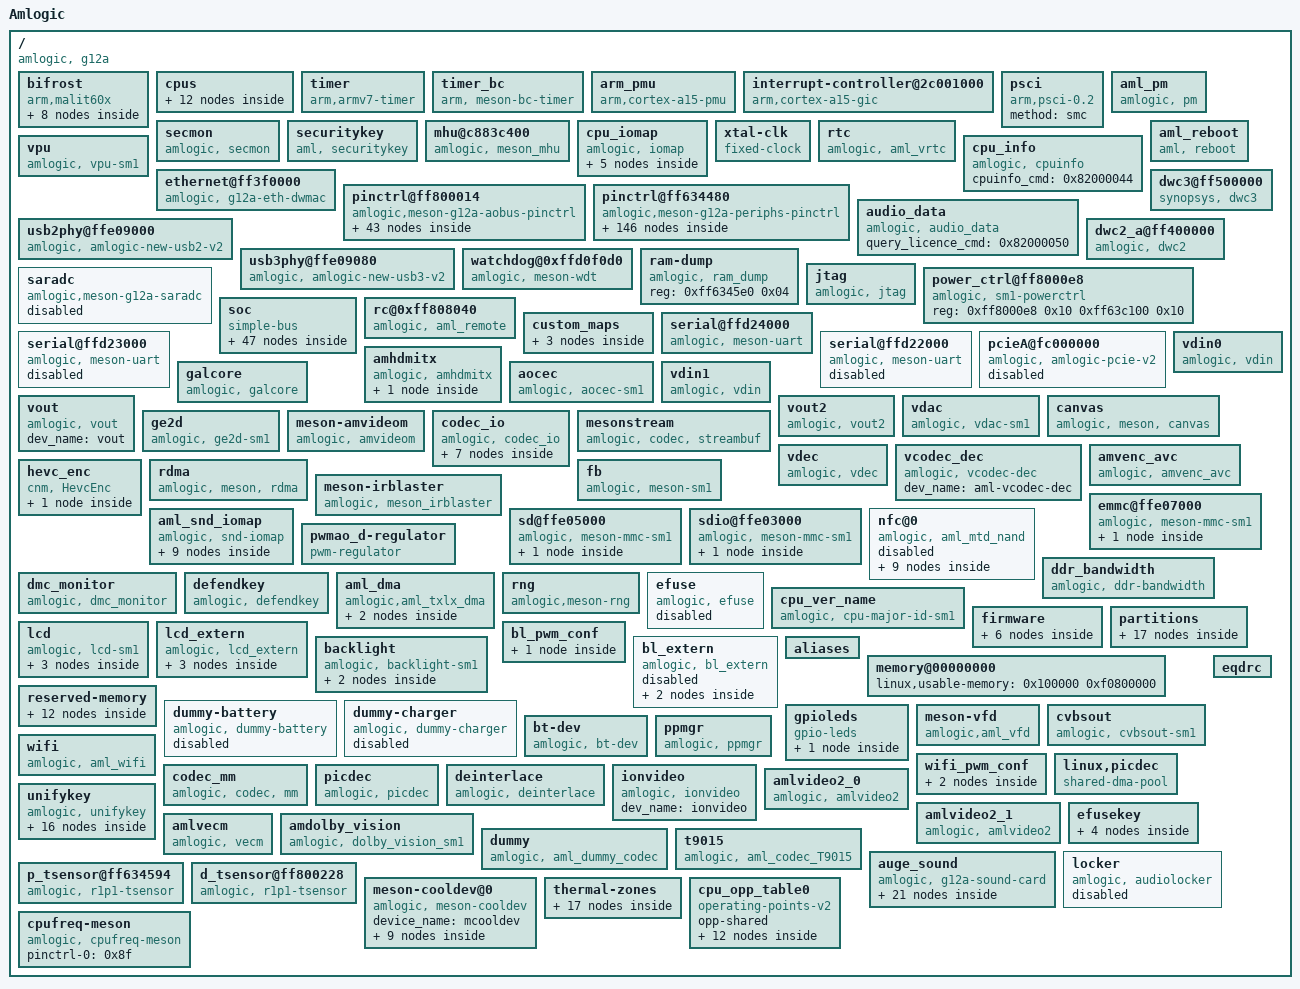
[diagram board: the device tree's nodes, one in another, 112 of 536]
/dts-v1/;

#include <dt-bindings/interrupt-controller/arm-gic.h>
#include <dt-bindings/clock/amlogic,g12a-clkc.h>
#include <dt-bindings/clock/amlogic,sm1-audio-clk.h>
#include <dt-bindings/iio/adc/amlogic-saradc.h>
#include <dt-bindings/gpio/meson-g12a-gpio.h>
#include <dt-bindings/pwm/pwm.h>
#include <dt-bindings/pwm/meson.h>
#include <dt-bindings/gpio/gpio.h>
#include <dt-bindings/input/input.h>
#include <dt-bindings/input/meson_rc.h>
#include <dt-bindings/phy/phy-amlogic-pcie.h>

/ {
	model = "Amlogic";
	amlogic-dt-id = "sm1_ac213_4g";
	compatible = "amlogic, g12a";
	interrupt-parent = <0x01>;
	#address-cells = <0x01>;
	#size-cells = <0x01>;

	bifrost {
		compatible = "arm,malit60x\0arm,malit6xx\0arm,mali-midgard";
		#cooling-cells = <0x02>;
		reg = <0xffe40000 0x4000 0xffd01000 0x1000 0xff800000 0x1000 0xff63c000 0x1000 0xffd01000 0x1000>;
		interrupt-parent = <0x01>;
		interrupts = <0x00 0xa0 0x04 0x00 0xa1 0x04 0x00 0xa2 0x04>;
		interrupt-names = "GPU\0MMU\0JOB";
		num_of_pp = <0x02>;
		sc_mpp = <0x01>;
		clocks = <0x02 0x83 0x02 0x07>;
		clock-names = "gpu_mux\0gp0_pll";
		tbl = <0x03 0x04 0x05 0x06 0x07 0x07>;
		phandle = <0x90>;

		clk125_cfg {
			clk_freq = <0x7735940>;
			clk_parent = "fclk_div4";
			clkp_freq = <0x1dcd6500>;
			clk_reg = <0xa03>;
			voltage = <0x47e>;
			keep_count = <0x05>;
			threshold = <0x1e 0x78>;
			phandle = <0x91>;
		};

		dvfs250_cfg {
			clk_freq = <0xee6b280>;
			clk_parent = "fclk_div4";
			clkp_freq = <0x1dcd6500>;
			clk_reg = <0xa01>;
			voltage = <0x47e>;
			keep_count = <0x05>;
			threshold = <0x50 0xaa>;
			phandle = <0x92>;
		};

		dvfs285_cfg {
			clk_freq = <0x1107a76d>;
			clk_parent = "fclk_div7";
			clkp_freq = <0x1107a76d>;
			clk_reg = <0xe00>;
			voltage = <0x47e>;
			keep_count = <0x05>;
			threshold = <0x64 0xbe>;
			phandle = <0x03>;
		};

		dvfs400_cfg {
			clk_freq = <0x17d78400>;
			clk_parent = "fclk_div5";
			clkp_freq = <0x17d78400>;
			clk_reg = <0xc00>;
			voltage = <0x47e>;
			keep_count = <0x05>;
			threshold = <0x98 0xcf>;
			phandle = <0x04>;
		};

		dvfs500_cfg {
			clk_freq = <0x1dcd6500>;
			clk_parent = "fclk_div4";
			clkp_freq = <0x1dcd6500>;
			clk_reg = <0xa00>;
			voltage = <0x47e>;
			keep_count = <0x05>;
			threshold = <0xb4 0xdc>;
			phandle = <0x05>;
		};

		dvfs666_cfg {
			clk_freq = <0x27bc86aa>;
			clk_parent = "fclk_div3";
			clkp_freq = <0x27bc86aa>;
			clk_reg = <0x800>;
			voltage = <0x47e>;
			keep_count = <0x05>;
			threshold = <0xd2 0xec>;
			phandle = <0x06>;
		};

		dvfs800_cfg {
			clk_freq = <0x2faf0800>;
			clk_parent = "fclk_div2p5";
			clkp_freq = <0x2faf0800>;
			clk_reg = <0x600>;
			voltage = <0x47e>;
			keep_count = <0x05>;
			threshold = <0xe6 0xff>;
			phandle = <0x93>;
		};

		dvfs850_cfg {
			clk_freq = <0x326cef80>;
			clk_parent = "gp0_pll";
			clkp_freq = <0x326cef80>;
			clk_reg = <0x200>;
			voltage = <0x47e>;
			keep_count = <0x05>;
			threshold = <0xe6 0xff>;
			phandle = <0x07>;
		};
	};

	cpus {
		#address-cells = <0x01>;
		#size-cells = <0x00>;
		phandle = <0x94>;

		cpu-map {

			cluster0 {
				phandle = <0x95>;

				core0 {
					cpu = <0x08>;
				};

				core1 {
					cpu = <0x09>;
				};

				core2 {
					cpu = <0x0a>;
				};

				core3 {
					cpu = <0x0b>;
				};
			};
		};

		cpu@0 {
			device_type = "cpu";
			compatible = "arm,cortex-a53\0arm,armv8";
			reg = <0x00>;
			enable-method = "psci";
			cpu-idle-states = <0x0c>;
			clocks = <0x02 0x17 0x02 0x16 0x02 0x00 0x02 0xf8 0x02 0xf7>;
			clock-names = "core_clk\0low_freq_clk_parent\0high_freq_clk_parent\0dsu_clk\0dsu_pre_parent";
			operating-points-v2 = <0x0d>;
			cpu-supply = <0x0e>;
			voltage-tolerance = <0x00>;
			clock-latency = <0xc350>;
			phandle = <0x08>;
		};

		cpu@1 {
			device_type = "cpu";
			compatible = "arm,cortex-a53\0arm,armv8";
			reg = <0x01>;
			enable-method = "psci";
			cpu-idle-states = <0x0c>;
			clocks = <0x02 0x17 0x02 0x16 0x02 0x00 0x02 0xf8 0x02 0xf7>;
			clock-names = "core_clk\0low_freq_clk_parent\0high_freq_clk_parent\0dsu_clk\0dsu_pre_parent";
			operating-points-v2 = <0x0d>;
			cpu-supply = <0x0e>;
			voltage-tolerance = <0x00>;
			clock-latency = <0xc350>;
			phandle = <0x09>;
		};

		cpu@2 {
			device_type = "cpu";
			compatible = "arm,cortex-a53\0arm,armv8";
			reg = <0x02>;
			enable-method = "psci";
			cpu-idle-states = <0x0c>;
			clocks = <0x02 0x17 0x02 0x16 0x02 0x00 0x02 0xf8 0x02 0xf7>;
			clock-names = "core_clk\0low_freq_clk_parent\0high_freq_clk_parent\0dsu_clk\0dsu_pre_parent";
			operating-points-v2 = <0x0d>;
			cpu-supply = <0x0e>;
			voltage-tolerance = <0x00>;
			clock-latency = <0xc350>;
			phandle = <0x0a>;
		};

		cpu@3 {
			device_type = "cpu";
			compatible = "arm,cortex-a53\0arm,armv8";
			reg = <0x03>;
			enable-method = "psci";
			cpu-idle-states = <0x0c>;
			clocks = <0x02 0x17 0x02 0x16 0x02 0x00 0x02 0xf8 0x02 0xf7>;
			clock-names = "core_clk\0low_freq_clk_parent\0high_freq_clk_parent\0dsu_clk\0dsu_pre_parent";
			operating-points-v2 = <0x0d>;
			cpu-supply = <0x0e>;
			voltage-tolerance = <0x00>;
			clock-latency = <0xc350>;
			phandle = <0x0b>;
		};

		idle-states {
			entry-method = "arm,psci-0.2";

			cpu-sleep-0 {
				compatible = "arm,idle-state";
				arm,psci-suspend-param = <0x10000>;
				local-timer-stop;
				entry-latency-us = <0xfa0>;
				exit-latency-us = <0x1388>;
				min-residency-us = <0x2710>;
				phandle = <0x0c>;
			};
		};
	};

	timer {
		compatible = "arm,armv7-timer";
		interrupts = <0x01 0x0d 0xff08 0x01 0x0e 0xff08 0x01 0x0b 0xff08 0x01 0x0a 0xff08>;
	};

	timer_bc {
		compatible = "arm, meson-bc-timer";
		reg = <0xffd0f190 0x04 0xffd0f194 0x04>;
		timer_name = "Meson TimerF";
		clockevent-rating = <0x12c>;
		clockevent-shift = <0x14>;
		clockevent-features = <0x23>;
		interrupts = <0x00 0x3c 0x01>;
		bit_enable = <0x10>;
		bit_mode = <0x0c>;
		bit_resolution = <0x00>;
	};

	arm_pmu {
		compatible = "arm,cortex-a15-pmu";
		interrupts = <0x00 0x89 0x04>;
		reg = <0xff634680 0x04>;
		cpumasks = <0x0f>;
		relax-timer-ns = <0x989680>;
		max-wait-cnt = <0x2710>;
	};

	interrupt-controller@2c001000 {
		compatible = "arm,cortex-a15-gic\0arm,cortex-a9-gic";
		#interrupt-cells = <0x03>;
		#address-cells = <0x00>;
		interrupt-controller;
		reg = <0xffc01000 0x1000 0xffc02000 0x100>;
		interrupts = <0x01 0x09 0xf04>;
		phandle = <0x01>;
	};

	psci {
		compatible = "arm,psci-0.2";
		method = "smc";
	};

	aml_pm {
		compatible = "amlogic, pm";
		status = "okay";
		device_name = "aml_pm";
		debug_reg = <0xff8000a8>;
		exit_reg = <0xff80023c>;
	};

	secmon {
		compatible = "amlogic, secmon";
		memory-region = <0x0f>;
		in_base_func = <0x82000020>;
		out_base_func = <0x82000021>;
		reserve_mem_size = <0x300000>;
	};

	securitykey {
		compatible = "aml, securitykey";
		storage_query = <0x82000060>;
		storage_read = <0x82000061>;
		storage_write = <0x82000062>;
		storage_tell = <0x82000063>;
		storage_verify = <0x82000064>;
		storage_status = <0x82000065>;
		storage_list = <0x82000067>;
		storage_remove = <0x82000068>;
		storage_in_func = <0x82000023>;
		storage_out_func = <0x82000024>;
		storage_block_func = <0x82000025>;
		storage_size_func = <0x82000027>;
		storage_set_enctype = <0x8200006a>;
		storage_get_enctype = <0x8200006b>;
		storage_version = <0x8200006c>;
	};

	mhu@c883c400 {
		compatible = "amlogic, meson_mhu";
		reg = <0xff63c400 0x4c 0xfffe7000 0x800>;
		interrupts = <0x00 0xd1 0x01 0x00 0xd2 0x01>;
		#mbox-cells = <0x01>;
		mbox-names = "cpu_to_scp_low\0cpu_to_scp_high";
		mboxes = <0x10 0x00 0x10 0x01>;
		phandle = <0x10>;
	};

	cpu_iomap {
		compatible = "amlogic, iomap";
		#address-cells = <0x01>;
		#size-cells = <0x01>;
		ranges;

		io_cbus_base {
			reg = <0xffd00000 0x26fff>;
		};

		io_apb_base {
			reg = <0xffe01000 0x7f000>;
		};

		io_aobus_base {
			reg = <0xff800000 0xb000>;
		};

		io_vapb_base {
			reg = <0xff900000 0x50000>;
		};

		io_hiu_base {
			reg = <0xff63c000 0x2000>;
		};
	};

	xtal-clk {
		compatible = "fixed-clock";
		clock-frequency = <0x16e3600>;
		clock-output-names = "xtal";
		#clock-cells = <0x00>;
		phandle = <0x14>;
	};

	rtc {
		compatible = "amlogic, aml_vrtc";
		alarm_reg_addr = <0xff8000a8>;
		timer_e_addr = <0xffd0f188>;
		init_date = "2015/01/01";
		status = "okay";
	};

	cpu_info {
		compatible = "amlogic, cpuinfo";
		status = "okay";
		cpuinfo_cmd = <0x82000044>;
	};

	aml_reboot {
		compatible = "aml, reboot";
		sys_reset = <0x84000009>;
		sys_poweroff = <0x84000008>;
	};

	vpu {
		compatible = "amlogic, vpu-sm1";
		dev_name = "vpu";
		status = "okay";
		clocks = <0x02 0x95 0x02 0x4c 0x02 0x87 0x02 0x8b 0x02 0x8c>;
		clock-names = "vapb_clk\0vpu_intr_gate\0vpu_clk0\0vpu_clk1\0vpu_clk";
		clk_level = <0x07>;
		phandle = <0x96>;
	};

	ethernet@ff3f0000 {
		compatible = "amlogic, g12a-eth-dwmac\0snps,dwmac";
		reg = <0xff3f0000 0x10000 0xff634540 0x08 0xff64c000 0xa0 0xffd01008 0x04>;
		reg-names = "eth_base\0eth_cfg\0eth_pll\0eth_reset";
		interrupts = <0x00 0x08 0x01>;
		interrupt-names = "macirq";
		status = "okay";
		clocks = <0x02 0x38>;
		clock-names = "ethclk81";
		pll_val = <0x9c0040a 0x927e0000 0xac5f49e5>;
		analog_val = <0x20200000 0xc000 0x23>;
		pinctrl-names = "external_eth_pins";
		pinctrl-0 = <0x11>;
		mc_val = <0x1621>;
		cali_val = <0x30000>;
		internal_phy = <0x00>;
		phandle = <0x97>;
	};

	pinctrl@ff800014 {
		compatible = "amlogic,meson-g12a-aobus-pinctrl";
		#address-cells = <0x01>;
		#size-cells = <0x01>;
		ranges;
		phandle = <0x98>;

		ao-bank@ff800014 {
			reg = <0xff800014 0x08 0xff800024 0x14 0xff80001c 0x08>;
			reg-names = "mux\0gpio\0drive-strength";
			gpio-controller;
			#gpio-cells = <0x02>;
			phandle = <0x63>;
		};

		sd_to_ao_uart_clr_pins {
			phandle = <0x43>;

			mux {
				groups = "GPIOAO_0\0GPIOAO_1";
				function = "gpio_aobus";
			};
		};

		sd_to_ao_uart_pins {
			phandle = <0x45>;

			mux {
				groups = "uart_ao_tx_a\0uart_ao_rx_a";
				function = "uart_ao_a";
				bias-pull-up;
				input-enable;
			};
		};

		ao_uart {
			phandle = <0x99>;

			mux {
				groups = "uart_ao_tx_a\0uart_ao_rx_a";
				function = "uart_ao_a";
			};
		};

		ao_b_uart {
			phandle = <0x1c>;

			mux {
				groups = "uart_ao_tx_b_2\0uart_ao_rx_b_3";
				function = "uart_ao_b";
			};
		};

		ao_i2c_pins1 {
			phandle = <0x9a>;

			mux {
				groups = "i2c_ao_sck\0i2c_ao_sda";
				function = "i2c_ao";
				drive-strength = <0x02>;
			};
		};

		ao_i2c_pins2 {
			phandle = <0x9b>;

			mux {
				groups = "i2c_ao_sck_e\0i2c_ao_sda_e";
				function = "i2c_ao";
				drive-strength = <0x02>;
			};
		};

		ao_i2c_slave_pins {
			phandle = <0x1b>;

			mux {
				groups = "i2c_ao_slave_sck\0i2c_ao_slave_sda";
				function = "i2c_ao_slave";
			};
		};

		pwm_ao_a {
			phandle = <0x9c>;

			mux {
				groups = "pwm_ao_a";
				function = "pwm_ao_a";
			};
		};

		pwm_ao_a_hiz {
			phandle = <0x9d>;

			mux {
				groups = "pwm_ao_a_hiz";
				function = "pwm_ao_a";
			};
		};

		pwm_ao_b {
			phandle = <0x9e>;

			mux {
				groups = "pwm_ao_b";
				function = "pwm_ao_b";
			};
		};

		pwm_ao_c_pins1 {
			phandle = <0x9f>;

			mux {
				groups = "pwm_ao_c_4";
				function = "pwm_ao_c";
			};
		};

		pwm_ao_c_pins2 {
			phandle = <0xa0>;

			mux {
				groups = "pwm_ao_c_6";
				function = "pwm_ao_c";
			};
		};

		pwm_ao_c_hiz {
			phandle = <0xa1>;

			mux {
				groups = "pwm_ao_c_hiz_4";
				function = "pwm_ao_c";
			};
		};

		pwm_ao_d_pins1 {
			phandle = <0xa2>;

			mux {
				groups = "pwm_ao_d_5";
				function = "pwm_ao_d";
			};
		};

		pwm_ao_d_pins2 {
			phandle = <0xa3>;

			mux {
				groups = "pwm_ao_d_10";
				function = "pwm_ao_d";
			};
		};

		pwm_ao_d_pins3 {
			phandle = <0x8f>;

			mux {
				groups = "pwm_ao_d_e";
				function = "pwm_ao_d";
			};
		};

		ao_ceca {
			phandle = <0xa4>;

			mux {
				groups = "cec_ao_a";
				function = "cec_ao";
			};
		};

		ao_cecb {
			phandle = <0xa5>;

			mux {
				groups = "cec_ao_b";
				function = "cec_ao";
			};
		};

		jtag_apao_pin {
			phandle = <0x15>;

			mux {
				groups = "jtag_a_tdi\0jtag_a_tdo\0jtag_a_clk\0jtag_a_tms";
				function = "jtag_a";
			};
		};

		remote_pin {
			phandle = <0x2a>;

			mux {
				groups = "remote_input_ao";
				function = "remote_input_ao";
			};
		};

		irblaster_pin {
			phandle = <0x3c>;

			mux {
				groups = "remote_out_ao";
				function = "remote_out_ao";
			};
		};
	};

	pinctrl@ff634480 {
		compatible = "amlogic,meson-g12a-periphs-pinctrl";
		#address-cells = <0x01>;
		#size-cells = <0x01>;
		ranges;
		phandle = <0xa6>;

		banks@ff6346c0 {
			reg = <0xff6346c0 0x40 0xff6344e8 0x18 0xff634520 0x18 0xff634440 0x4c 0xff634740 0x1c>;
			reg-names = "mux\0pull\0pull-enable\0gpio\0drive-strength";
			gpio-controller;
			#gpio-cells = <0x02>;
			phandle = <0x18>;
		};

		emmc_clk_cmd_pins {
			phandle = <0x3d>;

			mux {
				groups = "emmc_clk\0emmc_cmd";
				function = "emmc";
				input-enable;
				bias-pull-up;
				drive-strength = <0x03>;
			};
		};

		emmc_conf_pull_up {
			phandle = <0x3e>;

			mux {
				groups = "emmc_nand_d7\0emmc_nand_d6\0emmc_nand_d5\0emmc_nand_d4\0emmc_nand_d3\0emmc_nand_d2\0emmc_nand_d1\0emmc_nand_d0\0emmc_clk\0emmc_cmd";
				function = "emmc";
				input-enable;
				bias-pull-up;
				drive-strength = <0x03>;
			};
		};

		emmc_conf_pull_done {
			phandle = <0x3f>;

			mux {
				groups = "emmc_nand_ds";
				function = "emmc";
				input-enable;
				bias-pull-down;
				drive-strength = <0x03>;
			};
		};

		sd_clk_cmd_pins {
			phandle = <0x41>;

			mux {
				groups = "sdcard_cmd_c";
				function = "sdcard";
				input-enable;
				bias-pull-up;
				drive-strength = <0x03>;
			};

			mux1 {
				groups = "sdcard_clk_c";
				function = "sdcard";
				bias-pull-up;
				output-high;
				drive-strength = <0x03>;
			};
		};

		sd_all_pins {
			phandle = <0x40>;

			mux {
				groups = "sdcard_d0_c\0sdcard_d1_c\0sdcard_d2_c\0sdcard_d3_c\0sdcard_cmd_c";
				function = "sdcard";
				input-enable;
				bias-pull-up;
				drive-strength = <0x03>;
			};

			mux1 {
				groups = "sdcard_clk_c";
				function = "sdcard";
				bias-pull-up;
				output-high;
				drive-strength = <0x03>;
			};
		};

		sd_1bit_pins {
			phandle = <0x42>;

			mux {
				groups = "sdcard_d0_c\0sdcard_cmd_c";
				function = "sdcard";
				input-enable;
				bias-pull-up;
				drive-strength = <0x03>;
			};

			mux1 {
				groups = "sdcard_clk_c";
				function = "sdcard";
				bias-pull-up;
				output-high;
				drive-strength = <0x03>;
			};
		};

		sd_clr_all_pins {
			phandle = <0xa7>;

			mux {
				groups = "GPIOC_0\0GPIOC_1\0GPIOC_2\0GPIOC_3\0GPIOC_5";
				function = "gpio_periphs";
				output-high;
			};

			mux1 {
				groups = "GPIOC_4";
				function = "gpio_periphs";
				output-low;
			};
		};

		sd_clr_noall_pins {
			phandle = <0xa8>;

			mux {
				groups = "GPIOC_0\0GPIOC_1\0GPIOC_4\0GPIOC_5";
				function = "gpio_periphs";
				output-high;
			};
		};

		ao_to_sd_uart_pins {
			phandle = <0x44>;

			mux {
				groups = "uart_ao_tx_a_c3\0uart_ao_rx_a_c2";
				function = "uart_ao_a_ee";
				bias-pull-up;
				input-enable;
			};
		};

		sdio_clk_cmd_pins {
			phandle = <0x47>;

			mux {
				groups = "sdio_clk\0sdio_cmd";
				function = "sdio";
				input-enable;
				bias-pull-up;
				drive-strength = <0x03>;
			};
		};

		sdio_all_pins {
			phandle = <0x46>;

			mux {
				groups = "sdio_d0\0sdio_d1\0sdio_d2\0sdio_d3\0sdio_clk\0sdio_cmd";
				function = "sdio";
				input-enable;
				bias-pull-up;
				drive-strength = <0x03>;
			};
		};

		sdio_x_clk_cmd_pins {
			phandle = <0xa9>;

			mux {
				groups = "GPIOX_5";
				function = "gpio_periphs";
				input-enable;
				bias-pull-up;
				drive-strength = <0x03>;
			};

			mux1 {
				groups = "GPIOX_4";
				function = "gpio_periphs";
				bias-pull-up;
				output-high;
				drive-strength = <0x03>;
			};
		};

		sdio_x_all_pins {
			phandle = <0xaa>;

			mux {
				groups = "GPIOX_0\0GPIOX_1\0GPIOX_2\0GPIOX_3\0GPIOX_5";
				function = "gpio_periphs";
				input-enable;
				bias-pull-up;
				drive-strength = <0x03>;
			};

			mux1 {
				groups = "GPIOX_4";
				function = "gpio_periphs";
				bias-pull-up;
				output-high;
				drive-strength = <0x03>;
			};
		};

		sdio_x_en_pins {
			phandle = <0xab>;

			mux {
				groups = "sdio_dummy";
				function = "sdio";
				bias-pull-up;
				output-high;
			};
		};

		sdio_x_clr_pins {
			phandle = <0xac>;

			mux {
				groups = "GPIOV_0";
				function = "gpio_periphs";
				bias-pull-up;
				output-low;
			};

			mux1 {
				groups = "GPIOX_4";
				function = "gpio_periphs";
				output-low;
			};
		};

		all_nand_pins {
			phandle = <0x48>;

			mux {
				groups = "emmc_nand_d0\0emmc_nand_d1\0emmc_nand_d2\0emmc_nand_d3\0emmc_nand_d4\0emmc_nand_d5\0emmc_nand_d6\0emmc_nand_d7\0nand_ce0\0nand_ale\0nand_cle\0nand_wen_clk\0nand_ren_wr\0nand_rb0";
				function = "nand";
				input-enable;
			};
		};

		nand_cs {
			phandle = <0x49>;

			mux {
				groups = "nand_ce0";
				function = "nand";
			};
		};

		i2c0_pins1 {
			phandle = <0xad>;

			mux {
				groups = "i2c0_sda_c\0i2c0_sck_c";
				function = "i2c0";
				drive-strength = <0x02>;
			};
		};

		i2c0_pins2 {
			phandle = <0x17>;

			mux {
				groups = "i2c0_sda_z0\0i2c0_sck_z1";
				function = "i2c0";
				drive-strength = <0x02>;
			};
		};

		i2c0_pins3 {
			phandle = <0xae>;

			mux {
				groups = "i2c0_sda_z7\0i2c0_sck_z8";
				function = "i2c0";
				drive-strength = <0x02>;
			};
		};

		i2c1_pins1 {
			phandle = <0xaf>;

			mux {
				groups = "i2c1_sda_x\0i2c1_sck_x";
				function = "i2c1";
				drive-strength = <0x02>;
			};
		};

		i2c1_pins2 {
			phandle = <0xb0>;

			mux {
				groups = "i2c1_sda_h2\0i2c1_sck_h3";
				function = "i2c1";
				drive-strength = <0x02>;
			};
		};

		i2c1_pins3 {
			phandle = <0x19>;

			mux {
				groups = "i2c1_sda_h6\0i2c1_sck_h7";
				function = "i2c1";
				drive-strength = <0x02>;
			};
		};

		i2c2_pins1 {
			phandle = <0xb1>;

			mux {
				groups = "i2c2_sda_x\0i2c2_sck_x";
				function = "i2c2";
				drive-strength = <0x02>;
			};
		};

		i2c2_pins2 {
			phandle = <0xb2>;

			mux {
				groups = "i2c2_sda_z\0i2c2_sck_z";
				function = "i2c2";
				drive-strength = <0x02>;
			};
		};

		i2c2_pins3 {
			phandle = <0xb3>;

			mux {
				groups = "i2c2_sda_z10\0i2c2_sck_z11";
				function = "i2c2";
				drive-strength = <0x02>;
			};
		};

		i2c3_pins1 {
			phandle = <0x36>;

			mux {
				groups = "i2c3_sda_h\0i2c3_sck_h";
				function = "i2c3";
				drive-strength = <0x02>;
			};
		};

		i2c3_pins2 {
			phandle = <0x1a>;

			mux {
				function = "i2c3";
				drive-strength = <0x02>;
			};
		};

		pwm_a {
			phandle = <0xb4>;

			mux {
				groups = "pwm_a";
				function = "pwm_a";
			};
		};

		pwm_b_pins1 {
			phandle = <0xb5>;

			mux {
				groups = "pwm_b_x7";
				function = "pwm_b";
			};
		};

		pwm_b_pins2 {
			phandle = <0xb6>;

			mux {
				groups = "pwm_b_x19";
				function = "pwm_b";
			};
		};

		pwm_c_pins1 {
			phandle = <0xb7>;

			mux {
				groups = "pwm_c_c4";
				function = "pwm_c";
			};
		};

		pwm_c_pins2 {
			phandle = <0xb8>;

			mux {
				groups = "pwm_c_x5";
				function = "pwm_c";
			};
		};

		pwm_c_pins3 {
			phandle = <0xb9>;

			mux {
				groups = "pwm_c_x8";
				function = "pwm_c";
			};
		};

		pwm_d_pins1 {
			phandle = <0xba>;

			mux {
				groups = "pwm_d_x3";
				function = "pwm_d";
			};
		};

		pwm_d_pins2 {
			phandle = <0xbb>;

			mux {
				groups = "pwm_d_x6";
				function = "pwm_d";
			};
		};

		pwm_e {
			phandle = <0x64>;

			mux {
				groups = "pwm_e";
				function = "pwm_e";
			};
		};

		pwm_f_pins1 {
			phandle = <0xbc>;

			mux {
				groups = "pwm_f_x";
				function = "pwm_f";
			};
		};

		pwm_f_pins2 {
			phandle = <0x60>;

			mux {
				groups = "pwm_f_h";
				function = "pwm_f";
			};
		};

		spicc0_pins_x {
			phandle = <0xbd>;

			mux {
				groups = "spi0_mosi_x\0spi0_miso_x\0spi0_clk_x";
				function = "spi0";
				drive-strength = <0x01>;
			};
		};

		spicc0_pins_c {
			phandle = <0xbe>;

			mux {
				groups = "spi0_mosi_c\0spi0_miso_c\0spi0_ss0_c\0spi0_clk_c";
				function = "spi0";
				drive-strength = <0x01>;
			};
		};

		spicc1_pins {
			phandle = <0xbf>;

			mux {
				groups = "spi1_mosi\0spi1_miso\0spi1_clk";
				function = "spi1";
				drive-strength = <0x01>;
			};
		};

		a_uart {
			phandle = <0x2f>;

			mux {
				groups = "uart_tx_a\0uart_rx_a\0uart_cts_a\0uart_rts_a";
				function = "uart_a";
			};
		};

		b_uart {
			phandle = <0x30>;

			mux {
				groups = "uart_tx_b\0uart_rx_b";
				function = "uart_b";
			};
		};

		c_uart {
			phandle = <0x31>;

			mux {
				groups = "uart_tx_c\0uart_rx_c";
				function = "uart_c";
			};
		};

		hdmitx_hpd {
			phandle = <0x33>;

			mux {
				groups = "hdmitx_hpd_in";
				function = "hdmitx";
				bias-disable;
			};
		};

		hdmitx_hpd_gpio {
			phandle = <0x35>;

			mux {
				groups = "GPIOH_1";
				function = "gpio_periphs";
				bias-disable;
			};
		};

		hdmitx_ddc {
			phandle = <0x34>;

			mux {
				groups = "hdmitx_sda\0hdmitx_sck";
				function = "hdmitx";
				bias-disable;
				drive-strength = <0x03>;
			};
		};

		ee_ceca {
			phandle = <0x37>;

			mux {
				groups = "cec_ao_a_ee";
				function = "cec_ao_ee";
			};
		};

		ee_cecb {
			phandle = <0x38>;

			mux {
				groups = "cec_ao_b_ee";
				function = "cec_ao_ee";
			};
		};

		internal_eth_pins {
			phandle = <0xc0>;

			mux {
				function = "eth";
			};
		};

		internal_gpio_pins {
			phandle = <0xc1>;

			mux {
				function = "gpio_periphs";
				bias-disable;
				input-enable;
			};
		};

		external_eth_pins {
			phandle = <0x11>;

			mux {
				groups = "eth_mdio\0eth_mdc\0eth_rgmii_rx_clk\0eth_rx_dv\0eth_rxd0\0eth_rxd1\0eth_rxd2_rgmii\0eth_rxd3_rgmii\0eth_rgmii_tx_clk\0eth_txen\0eth_txd0\0eth_txd1\0eth_txd2_rgmii\0eth_txd3_rgmii";
				function = "eth";
				drive-strength = <0x03>;
			};
		};

		jtag_apee_pin {
			phandle = <0x16>;

			mux {
				groups = "jtag_b_tdi\0jtag_b_tdo\0jtag_b_clk\0jtag_b_tms";
				function = "jtag_b";
			};
		};

		tdmout_a {
			phandle = <0x1f>;

			mux {
				groups = "tdma_sclk\0tdma_fs\0tdma_dout0";
				function = "tdma_out";
			};
		};

		tdmin_a {
			phandle = <0x20>;

			mux {
				groups = "tdma_din1";
				function = "tdma_in";
			};
		};

		tdmb_mclk {
			phandle = <0x21>;

			mux {
				groups = "mclk0_a";
				function = "mclk0";
				drive-strength = <0x02>;
			};
		};

		tdmout_b {
			phandle = <0x22>;

			mux {
				groups = "tdmb_sclk\0tdmb_fs\0tdmb_dout0";
				function = "tdmb_out";
				drive-strength = <0x02>;
			};
		};

		tdmin_b {
			phandle = <0x23>;

			mux {
				groups = "tdmb_din1";
				function = "tdmb_in";
				drive-strength = <0x02>;
			};
		};

		tdmc_mclk {
			phandle = <0x24>;

			mux {
				groups = "mclk1_a";
				function = "mclk1";
			};
		};

		tdmout_c {
			phandle = <0x25>;

			mux {
				groups = "tdmc_sclk_a\0tdmc_fs_a\0tdmc_dout0_a";
				function = "tdmc_out";
			};
		};

		tdmin_c {
			phandle = <0x26>;

			mux {
				groups = "tdmc_din0_a";
				function = "tdmc_in";
			};
		};

		spdifin {
			phandle = <0x28>;

			mux {
				groups = "spdif_in_h";
				function = "spdif_in";
			};
		};

		pdmin {
			phandle = <0x29>;

			mux {
				groups = "pdm_din0_a\0pdm_din2_a\0pdm_dclk_a";
				function = "pdm";
			};
		};

		bl_pwm_off_pin {
			phandle = <0xc2>;

			mux {
				pins = "GPIOH_5";
				function = "gpio_periphs";
				output-high;
			};
		};

		clk12_24_z_pins {
			phandle = <0xc3>;

			mux {
				groups = "clk12_24_z";
				function = "clk12_24_ee";
				drive-strength = <0x03>;
			};
		};

		gen_clk_ee_z {
			phandle = <0xc4>;

			mux {
				groups = "gen_clk_ee_z";
				function = "gen_clk_ee";
				drive-strength = <0x03>;
			};
		};

		cam_dvp_pins {
			phandle = <0xc5>;

			mux {
				groups = "bt656_a_vs\0bt656_a_hs\0bt656_a_clk\0bt656_a_din0\0bt656_a_din1\0bt656_a_din2\0bt656_a_din3\0bt656_a_din4\0bt656_a_din5\0bt656_a_din6\0bt656_a_din7";
				function = "bt656";
			};
		};

		spdifout {
			phandle = <0x27>;

			mux {
				groups = "spdif_out_h";
				function = "spdif_out";
			};
		};
	};

	audio_data {
		compatible = "amlogic, audio_data";
		query_licence_cmd = <0x82000050>;
		status = "okay";
		phandle = <0xc6>;
	};

	dwc3@ff500000 {
		compatible = "synopsys, dwc3";
		status = "okay";
		reg = <0xff500000 0x100000>;
		interrupts = <0x00 0x1e 0x04>;
		usb-phy = <0x12 0x13>;
		cpu-type = "gxl";
		clock-src = "usb3.0";
		clocks = <0x02 0x41>;
		clock-names = "dwc_general";
		phandle = <0xc7>;
	};

	usb2phy@ffe09000 {
		compatible = "amlogic, amlogic-new-usb2-v2";
		status = "okay";
		reg = <0xffe09000 0x80 0xffd01008 0x100 0xff636000 0x2000 0xff63a000 0x2000>;
		pll-setting-1 = <0x9400414>;
		pll-setting-2 = <0x927e0000>;
		pll-setting-3 = <0xac5f69e5>;
		pll-setting-4 = <0xfe18>;
		pll-setting-5 = <0x8000fff>;
		pll-setting-6 = <0x78000>;
		pll-setting-7 = <0xe0004>;
		pll-setting-8 = <0xe000c>;
		version = <0x02>;
		pwr-ctl = <0x01>;
		u2-ctrl-sleep-shift = <0x11>;
		u2-hhi-mem-pd-shift = <0x1e>;
		u2-hhi-mem-pd-mask = <0x03>;
		u2-ctrl-iso-shift = <0x11>;
		portnum = <0x02>;
		phandle = <0x12>;
	};

	usb3phy@ffe09080 {
		compatible = "amlogic, amlogic-new-usb3-v2";
		status = "okay";
		reg = <0xffe09080 0x20 0xffd01008 0x100>;
		phy-reg = <0xff646000>;
		phy-reg-size = <0x2000>;
		usb2-phy-reg = <0xffe09000>;
		usb2-phy-reg-size = <0x80>;
		interrupts = <0x00 0x10 0x04>;
		clocks = <0x02 0x18>;
		clock-names = "pcie_refpll";
		pwr-ctl = <0x01>;
		u3-ctrl-sleep-shift = <0x12>;
		u3-hhi-mem-pd-shift = <0x1a>;
		u3-hhi-mem-pd-mask = <0x0f>;
		u3-ctrl-iso-shift = <0x12>;
		portnum = <0x01>;
		otg = <0x00>;
		phandle = <0x13>;
	};

	dwc2_a@ff400000 {
		compatible = "amlogic, dwc2";
		status = "okay";
		device_name = "dwc2_a";
		reg = <0xff400000 0x40000>;
		interrupts = <0x00 0x1f 0x04>;
		pl-periph-id = <0x00>;
		clock-src = "usb0";
		port-id = <0x00>;
		port-type = <0x02>;
		port-speed = <0x00>;
		port-config = <0x00>;
		port-dma = <0x00>;
		port-id-mode = <0x00>;
		usb-fifo = <0x2d8>;
		cpu-type = "v2";
		phy-reg = <0xffe09000>;
		phy-reg-size = <0xa0>;
		phy-interface = <0x02>;
		clocks = <0x02 0x41 0x02 0x49>;
		clock-names = "usb_general\0usb1";
		controller-type = <0x01>;
		phandle = <0xc8>;
	};

	watchdog@0xffd0f0d0 {
		compatible = "amlogic, meson-wdt";
		status = "okay";
		default_timeout = <0x0a>;
		reset_watchdog_method = <0x01>;
		reset_watchdog_time = <0x02>;
		shutdown_timeout = <0x0a>;
		firmware_timeout = <0x06>;
		suspend_timeout = <0x06>;
		reg = <0xffd0f0d0 0x10>;
		clock-names = "xtal";
		clocks = <0x14>;
		phandle = <0xc9>;
	};

	ram-dump {
		compatible = "amlogic, ram_dump";
		status = "okay";
		reg = <0xff6345e0 0x04>;
		reg-names = "PREG_STICKY_REG8";
	};

	jtag {
		compatible = "amlogic, jtag";
		status = "okay";
		select = "disable";
		pinctrl-names = "jtag_apao_pins\0jtag_apee_pins";
		pinctrl-0 = <0x15>;
		pinctrl-1 = <0x16>;
	};

	saradc {
		compatible = "amlogic,meson-g12a-saradc";
		status = "disabled";
		#io-channel-cells = <0x01>;
		clocks = <0x14 0x02 0x105>;
		clock-names = "xtal\0saradc_clk";
		interrupts = <0x00 0xc8 0x01>;
		reg = <0xff809000 0x48>;
		phandle = <0xca>;
	};

	power_ctrl@ff8000e8 {
		compatible = "amlogic, sm1-powerctrl";
		reg = <0xff8000e8 0x10 0xff63c100 0x10>;
		phandle = <0xcb>;
	};

	soc {
		compatible = "simple-bus";
		#address-cells = <0x01>;
		#size-cells = <0x01>;
		ranges;

		cbus@ffd00000 {
			compatible = "simple-bus";
			reg = <0xffd00000 0x26000>;
			#address-cells = <0x01>;
			#size-cells = <0x01>;
			ranges = <0x00 0xffd00000 0x26000>;
			phandle = <0xcc>;

			interrupt-controller@f080 {
				compatible = "amlogic,meson-gpio-intc\0amlogic,meson-sm1-gpio-intc";
				reg = <0xf080 0x10>;
				interrupt-controller;
				#interrupt-cells = <0x02>;
				amlogic,channel-interrupts = <0x40 0x41 0x42 0x43 0x44 0x45 0x46 0x47>;
				status = "okay";
				phandle = <0xcd>;
			};

			meson_clk_msr {
				compatible = "amlogic, sm1-measure";
				reg = <0x18004 0x04 0x1800c 0x04>;
				ringctrl = <0xff6345fc>;
			};

			pwm@1b000 {
				compatible = "amlogic,g12a-ee-pwm";
				reg = <0x1b000 0x20>;
				#pwm-cells = <0x03>;
				clocks = <0x14 0x14 0x14 0x14>;
				clock-names = "clkin0\0clkin1\0clkin2\0clkin3";
				status = "disabled";
				phandle = <0xce>;
			};

			pwm@1a000 {
				compatible = "amlogic,g12a-ee-pwm";
				reg = <0x1a000 0x20>;
				#pwm-cells = <0x03>;
				clocks = <0x14 0x14 0x14 0x14>;
				clock-names = "clkin0\0clkin1\0clkin2\0clkin3";
				status = "disabled";
				phandle = <0xcf>;
			};

			pwm@19000 {
				compatible = "amlogic,g12a-ee-pwm";
				reg = <0x19000 0x20>;
				#pwm-cells = <0x03>;
				clocks = <0x14 0x14 0x14 0x14>;
				clock-names = "clkin0\0clkin1\0clkin2\0clkin3";
				status = "okay";
				phandle = <0x62>;
			};

			i2c@1f000 {
				compatible = "amlogic,meson-g12a-i2c";
				status = "okay";
				reg = <0x1f000 0x20>;
				interrupts = <0x00 0x15 0x01 0x00 0x5b 0x01>;
				#address-cells = <0x01>;
				#size-cells = <0x00>;
				clocks = <0x02 0x2a>;
				clock-names = "clk_i2c";
				pinctrl-names = "default";
				pinctrl-0 = <0x17>;
				clock-frequency = <0x61a80>;
				phandle = <0xd0>;

				gt9xx@5d {
					compatible = "goodix,gt9xx";
					status = "disabled";
					reg = <0x5d>;
					reset-gpio = <0x18 0x0a 0x00>;
					irq-gpio = <0x18 0x04 0x00>;
				};

				ftxx@38 {
					compatible = "focaltech,fts";
					status = "disabled";
					reg = <0x38>;
					reset-gpio = <0x18 0x0a 0x00>;
					irq-gpio = <0x18 0x04 0x00>;
					x_max = <0x258>;
					y_max = <0x400>;
					max-touch-number = <0x0a>;
				};
			};

			i2c@1e000 {
				compatible = "amlogic,meson-g12a-i2c";
				status = "disabled";
				reg = <0x1e000 0x20>;
				interrupts = <0x00 0xd6 0x01 0x00 0x5c 0x01>;
				#address-cells = <0x01>;
				#size-cells = <0x00>;
				clocks = <0x02 0x2a>;
				clock-names = "clk_i2c";
				pinctrl-names = "default";
				pinctrl-0 = <0x19>;
				clock-frequency = <0x186a0>;
				phandle = <0xd1>;

				hym8563@51 {
					compatible = "haoyu,hym8563";
					status = "disabled";
					reg = <0x51>;
					#clock-cells = <0x00>;
					phandle = <0xd2>;
				};
			};

			i2c@1d000 {
				compatible = "amlogic,meson-g12a-i2c";
				status = "disabled";
				reg = <0x1d000 0x20>;
				interrupts = <0x00 0xd7 0x01 0x00 0x5e 0x01>;
				#address-cells = <0x01>;
				#size-cells = <0x00>;
				clocks = <0x02 0x2a>;
				clock-names = "clk_i2c";
				phandle = <0xd3>;
			};

			i2c@1c000 {
				compatible = "amlogic,meson-g12a-i2c";
				status = "ok";
				reg = <0x1c000 0x20>;
				interrupts = <0x00 0x27 0x01 0x00 0x5f 0x01>;
				#address-cells = <0x01>;
				#size-cells = <0x00>;
				clocks = <0x02 0x2a>;
				clock-names = "clk_i2c";
				pinctrl-names = "default";
				pinctrl-0 = <0x1a>;
				clock-frequency = <0x186a0>;
				phandle = <0xd4>;

				ad82584f_62@62 {
					compatible = "ESMT, ad82584f";
					#sound-dai-cells = <0x00>;
					reg = <0x31>;
					status = "disabled";
					reset_pin = <0x18 0x37 0x00>;
					no_mclk;
					phandle = <0xd5>;
				};

				bl_extern_i2c {
					compatible = "bl_extern, i2c";
					dev_name = "lp8556";
					reg = <0x2c>;
					status = "disabled";
				};
			};

			spi@13000 {
				compatible = "amlogic,meson-g12a-spicc";
				reg = <0x13000 0x44>;
				interrupts = <0x00 0x51 0x04>;
				clocks = <0x02 0x29 0x02 0xd1>;
				clock-names = "core\0comp";
				#address-cells = <0x01>;
				#size-cells = <0x00>;
				status = "disabled";
				phandle = <0xd6>;
			};

			spi@15000 {
				compatible = "amlogic,meson-g12a-spicc";
				reg = <0x15000 0x44>;
				interrupts = <0x00 0x5a 0x04>;
				clocks = <0x02 0x2f 0x02 0xd5>;
				clock-names = "core\0comp";
				#address-cells = <0x01>;
				#size-cells = <0x00>;
				status = "disabled";
				phandle = <0xd7>;
			};
		};

		aobus@ff800000 {
			compatible = "simple-bus";
			reg = <0xff800000 0xb000>;
			#address-cells = <0x01>;
			#size-cells = <0x01>;
			ranges = <0x00 0xff800000 0xb000>;
			phandle = <0xd8>;

			cpu_version {
				reg = <0x220 0x04>;
			};

			clock-controller@0 {
				compatible = "amlogic,sm1-aoclkc";
				#clock-cells = <0x01>;
				reg = <0x00 0x3dc>;
				phandle = <0xd9>;
			};

			pwm@7000 {
				compatible = "amlogic,g12a-ao-pwm";
				reg = <0x7000 0x20>;
				#pwm-cells = <0x03>;
				clocks = <0x14 0x14 0x14 0x14>;
				clock-names = "clkin0\0clkin1\0clkin2\0clkin3";
				status = "disabled";
				phandle = <0xda>;
			};

			pwm@2000 {
				compatible = "amlogic,g12a-ao-pwm";
				reg = <0x2000 0x20>;
				#pwm-cells = <0x03>;
				clocks = <0x14 0x14 0x14 0x14>;
				clock-names = "clkin0\0clkin1\0clkin2\0clkin3";
				status = "okay";
				phandle = <0x4d>;
			};

			i2c@5000 {
				compatible = "amlogic,meson-g12a-i2c";
				status = "disabled";
				reg = <0x5000 0x20>;
				interrupts = <0x00 0xc3 0x01 0x00 0xc9 0x01>;
				#address-cells = <0x01>;
				#size-cells = <0x00>;
				clocks = <0x02 0x2a>;
				clock-names = "clk_i2c";
				phandle = <0xdb>;
			};

			i2c_slave@6000 {
				compatible = "amlogic, meson-i2c-slave";
				status = "disabled";
				reg = <0x6000 0x20>;
				interrupts = <0x00 0xc2 0x01>;
				pinctrl-names = "default";
				pinctrl-0 = <0x1b>;
				phandle = <0xdc>;
			};

			serial@3000 {
				compatible = "amlogic, meson-uart";
				reg = <0x3000 0x18>;
				interrupts = <0x00 0xc1 0x01>;
				status = "okay";
				clocks = <0x14>;
				clock-names = "clk_uart";
				xtal_tick_en = <0x02>;
				fifosize = <0x40>;
				pinctrl-names = "default";
				support-sysrq = <0x00>;
				phandle = <0xdd>;
			};

			serial@4000 {
				compatible = "amlogic, meson-uart";
				reg = <0x4000 0x18>;
				interrupts = <0x00 0xc5 0x01>;
				status = "disabled";
				clocks = <0x14>;
				clock-names = "clk_uart";
				fifosize = <0x40>;
				pinctrl-names = "default";
				pinctrl-0 = <0x1c>;
				phandle = <0xde>;
			};
		};

		periphs@ff634400 {
			compatible = "simple-bus";
			reg = <0xff634400 0x400>;
			#address-cells = <0x01>;
			#size-cells = <0x01>;
			ranges = <0x00 0xff634400 0x400>;
			phandle = <0xdf>;
		};

		hiubus@ff63c000 {
			compatible = "simple-bus";
			reg = <0xff63c000 0x2000>;
			#address-cells = <0x01>;
			#size-cells = <0x01>;
			ranges = <0x00 0xff63c000 0x2000>;
			phandle = <0xe0>;

			clock-controller@0 {
				compatible = "amlogic,sm1-clkc-1";
				#clock-cells = <0x01>;
				reg = <0x00 0x3dc>;
				phandle = <0x02>;
			};

			clock-controller@1 {
				compatible = "amlogic,sm1-clkc-2";
				#clock-cells = <0x01>;
				reg = <0x00 0x3dc>;
				own-dsu-clk;
				phandle = <0xe1>;
			};
		};

		ion_dev {
			compatible = "amlogic, ion_dev";
			memory-region = <0x1d>;
		};

		audiobus@0xFF660000 {
			compatible = "amlogic, audio-controller\0simple-bus";
			reg = <0xff660000 0x4000>;
			#address-cells = <0x01>;
			#size-cells = <0x01>;
			ranges = <0x00 0xff660000 0x4000>;
			phandle = <0xe2>;

			audio_clocks {
				compatible = "amlogic, sm1-audio-clocks";
				#clock-cells = <0x01>;
				reg = <0x00 0xb0>;
				phandle = <0x1e>;
			};

			ddr_manager {
				compatible = "amlogic, sm1-audio-ddr-manager";
				interrupts = <0x00 0x94 0x01 0x00 0x95 0x01 0x00 0x96 0x01 0x00 0x31 0x01 0x00 0x98 0x01 0x00 0x99 0x01 0x00 0x9a 0x01 0x00 0x32 0x01>;
				interrupt-names = "toddr_a\0toddr_b\0toddr_c\0toddr_d\0frddr_a\0frddr_b\0frddr_c\0frddr_d";
			};

			tdm@0 {
				compatible = "amlogic, sm1-snd-tdma";
				#sound-dai-cells = <0x00>;
				dai-tdm-lane-slot-mask-in = <0x00 0x01>;
				dai-tdm-oe-lane-slot-mask-out = <0x01 0x00>;
				dai-tdm-clk-sel = <0x00>;
				clocks = <0x1e 0x24 0x02 0x0c>;
				clock-names = "mclk\0clk_srcpll";
				pinctrl-names = "tdm_pins";
				pinctrl-0 = <0x1f 0x20>;
				status = "okay";
				phandle = <0x7f>;
			};

			tdm@1 {
				compatible = "amlogic, sm1-snd-tdmb";
				#sound-dai-cells = <0x00>;
				dai-tdm-lane-slot-mask-in = <0x00 0x01 0x00 0x00>;
				dai-tdm-lane-slot-mask-out = <0x01 0x00 0x00 0x00>;
				dai-tdm-clk-sel = <0x01>;
				clocks = <0x1e 0x25 0x02 0x0d 0x02 0x0c 0x1e 0x2b>;
				clock-names = "mclk\0clk_srcpll\0samesource_srcpll\0samesource_clk";
				pinctrl-names = "tdm_pins";
				pinctrl-0 = <0x21 0x22 0x23>;
				mclk_pad = <0x00>;
				samesource_sel = <0x03>;
				start_clk_enable = <0x01>;
				clk_tuning_enable = <0x01>;
				status = "okay";
				phandle = <0x81>;
			};

			tdm@2 {
				compatible = "amlogic, sm1-snd-tdmc";
				#sound-dai-cells = <0x00>;
				dai-tdm-lane-slot-mask-in = <0x01 0x00 0x00 0x00>;
				#dai-tdm-lane-slot-mask-out = <0x01 0x00 0x01 0x01>;
				#dai-tdm-lane-oe-slot-mask-in = <0x00 0x00 0x00 0x00>;
				#dai-tdm-lane-oe-slot-mask-out = <0x01 0x00 0x00 0x00>;
				dai-tdm-clk-sel = <0x02>;
				clocks = <0x1e 0x26 0x02 0x0e>;
				clock-names = "mclk\0clk_srcpll";
				pinctrl-names = "tdm_pins";
				pinctrl-0 = <0x24 0x25 0x26>;
				mclk_pad = <0x00>;
				status = "okay";
				phandle = <0x83>;
			};

			tdm@3 {
				compatible = "amlogic, sm1-snd-tdmlb";
				#sound-dai-cells = <0x00>;
				dai-tdm-lane-lb-slot-mask-in = <0x01 0x00 0x00 0x00>;
				dai-tdm-clk-sel = <0x01>;
				clocks = <0x1e 0x25 0x02 0x0d>;
				clock-names = "mclk\0clk_srcpll";
				lb-src-sel = <0x01>;
				status = "disabled";
				phandle = <0xe3>;
			};

			spdif@0 {
				compatible = "amlogic, sm1-snd-spdif-a";
				#sound-dai-cells = <0x00>;
				clocks = <0x02 0x0c 0x02 0x04 0x1e 0x10 0x1e 0x11 0x1e 0x2a 0x1e 0x2b>;
				clock-names = "sysclk\0fixed_clk\0gate_spdifin\0gate_spdifout\0clk_spdifin\0clk_spdifout";
				interrupts = <0x00 0x97 0x01>;
				interrupt-names = "irq_spdifin";
				pinctrl-names = "spdif_pins";
				pinctrl-0 = <0x27 0x28>;
				clk_tuning_enable = <0x01>;
				status = "okay";
				phandle = <0x85>;
			};

			spdif@1 {
				compatible = "amlogic, sm1-snd-spdif-b";
				#sound-dai-cells = <0x00>;
				clocks = <0x02 0x0c 0x1e 0x15 0x1e 0x31>;
				clock-names = "sysclk\0gate_spdifout\0clk_spdifout";
				status = "okay";
				phandle = <0x86>;
			};

			pdm {
				compatible = "amlogic, sm1-snd-pdm";
				#sound-dai-cells = <0x00>;
				clocks = <0x1e 0x01 0x02 0x03 0x02 0x0f 0x1e 0x2f 0x1e 0x30>;
				clock-names = "gate\0sysclk_srcpll\0dclk_srcpll\0pdm_dclk\0pdm_sysclk";
				pinctrl-names = "pdm_pins";
				pinctrl-0 = <0x29>;
				filter_mode = <0x01>;
				status = "okay";
				phandle = <0x84>;
			};

			earc {
				compatible = "amlogic, sm1-snd-earc";
				#sound-dai-cells = <0x00>;
				clocks = <0x1e 0x23 0x1e 0x38 0x1e 0x39 0x02 0x05 0x02 0x03>;
				clock-names = "rx_gate\0rx_cmdc\0rx_dmac\0rx_cmdc_srcpll\0rx_dmac_srcpll";
				interrupts = <0x00 0x58 0x01 0x00 0x57 0x01>;
				interrupt-names = "rx_cmdc\0rx_dmac";
				status = "okay";
				phandle = <0x87>;
			};

			resample@0 {
				compatible = "amlogic, sm1-resample";
				clocks = <0x02 0x0f 0x1e 0x29 0x1e 0x2c>;
				clock-names = "resample_pll\0resample_src\0resample_clk";
				resample_module = <0x04>;
				status = "okay";
				phandle = <0xe4>;
			};

			vad {
				compatible = "amlogic, snd-vad";
				#sound-dai-cells = <0x00>;
				clocks = <0x1e 0x1b 0x02 0x05 0x1e 0x35>;
				clock-names = "gate\0pll\0clk";
				interrupts = <0x00 0x9b 0x01 0x00 0x30 0x01>;
				interrupt-names = "irq_wakeup\0irq_frame_sync";
				src = <0x04>;
				level = <0x01>;
				status = "okay";
				phandle = <0xe5>;
			};

			loopback@0 {
				compatible = "amlogic, sm1-loopbacka";
				#sound-dai-cells = <0x00>;
				clocks = <0x1e 0x01 0x02 0x03 0x02 0x0f 0x1e 0x2f 0x1e 0x30 0x02 0x0c 0x1e 0x24>;
				clock-names = "pdm_gate\0pdm_sysclk_srcpll\0pdm_dclk_srcpll\0pdm_dclk\0pdm_sysclk\0tdminlb_mpll\0tdminlb_mclk";
				datain_src = <0x04>;
				datain_chnum = <0x02>;
				datain_chmask = <0x03>;
				datain-lane-mask-in = <0x01 0x00 0x00 0x00>;
				mclk-fs = <0x100>;
				datalb_src = <0x01>;
				datalb_chnum = <0x02>;
				datalb_chmask = <0x03>;
				datalb-lane-mask-in = <0x01 0x00 0x00 0x00>;
				status = "okay";
				phandle = <0xe6>;
			};

			loopback@1 {
				compatible = "amlogic, sm1-loopbackb";
				#sound-dai-cells = <0x00>;
				clocks = <0x1e 0x01 0x02 0x03 0x02 0x0f 0x1e 0x2f 0x1e 0x30 0x02 0x0c 0x1e 0x24>;
				clock-names = "pdm_gate\0pdm_sysclk_srcpll\0pdm_dclk_srcpll\0pdm_dclk\0pdm_sysclk\0tdminlb_mpll\0tdminlb_mclk";
				mclk-fs = <0x100>;
				datain_src = <0x04>;
				datain_chnum = <0x04>;
				datain_chmask = <0x0f>;
				datain-lane-mask-in = <0x01 0x00 0x01 0x00>;
				datalb_src = <0x01>;
				datalb_chnum = <0x02>;
				datalb_chmask = <0x03>;
				datalb-lane-mask-in = <0x01 0x00 0x00 0x00>;
				status = "disabled";
				phandle = <0xe7>;
			};

			effect {
				compatible = "amlogic, snd-effect-v3";
				#sound-dai-cells = <0x00>;
				clocks = <0x1e 0x16 0x02 0x05 0x1e 0x34>;
				clock-names = "gate\0srcpll\0eqdrc";
				eqdrc_module = <0x01>;
				lane_mask = <0x01>;
				channel_mask = <0x03>;
				status = "okay";
				phandle = <0xe8>;
			};
		};
	};

	rc@0xff808040 {
		compatible = "amlogic, aml_remote";
		dev_name = "meson-remote";
		reg = <0xff808040 0x44 0xff808000 0x20>;
		status = "okay";
		protocol = <0x01>;
		led_blink = <0x01>;
		led_blink_frq = <0x64>;
		interrupts = <0x00 0xc4 0x01>;
		pinctrl-names = "default";
		pinctrl-0 = <0x2a>;
		map = <0x2b>;
		max_frame_time = <0xc8>;
		phandle = <0xe9>;
	};

	custom_maps {
		mapnum = <0x03>;
		map0 = <0x2c>;
		map1 = <0x2d>;
		map2 = <0x2e>;
		phandle = <0x2b>;

		map_0 {
			mapname = "amlogic-remote-1";
			customcode = <0xfb04>;
			release_delay = <0x50>;
			size = <0x32>;
			keymap = <0x47000b 0x130002 0x100003 0x110004 0xf0005 0xc0006 0xd0007 0xb0008 0x80009 0x9000a 0x5c0061 0x51003d 0x50003e 0x40003f 0x4d0040 0x430041 0x170042 0x43 0x10044 0x160057 0x49000e 0x60082 0x140083 0x440067 0x1d006c 0x1c0069 0x48006a 0x53007d 0x450068 0x19006d 0x520077 0x5007a 0x59007b 0x1b0078 0x40079 0x1a0074 0xa000f 0xe0071 0x1f0066 0x1e0084 0x70085 0x120086 0x540087 0x20088 0x4f001e 0x420030 0x5d002e 0x4c0020 0x580089 0x55008c>;
			phandle = <0x2c>;
		};

		map_1 {
			mapname = "amlogic-remote-2";
			customcode = <0xfe01>;
			release_delay = <0x50>;
			fn_key_scancode = <0x00>;
			cursor_left_scancode = <0x51>;
			cursor_right_scancode = <0x50>;
			cursor_up_scancode = <0x16>;
			cursor_down_scancode = <0x1a>;
			cursor_ok_scancode = <0x13>;
			size = <0x2d>;
			keymap = <0x1000b 0x4e0002 0xd0003 0xc0004 0x4a0005 0x90006 0x80007 0x460008 0x50009 0x4000a 0x49003f 0x48004e 0x4d004b 0x3004c 0x43004d 0x450040 0xf0041 0x440042 0x120043 0x4b0044 0x260045 0x160067 0x1a006c 0x510069 0x50006a 0x13001c 0x19009e 0x4c007d 0x400074 0x410071 0x180073 0x100072 0x110066 0xa006f 0x42000e 0x4700d7 0xe0046 0x59007a 0x58007b 0x540078 0x52007c 0x5a0077 0x550079 0x64 0x1b00bc>;
			phandle = <0x2d>;
		};

		map_2 {
			mapname = "amlogic-remote-3";
			customcode = <0xbd02>;
			release_delay = <0x50>;
			size = <0x11>;
			keymap = <0xca0067 0xd2006c 0x990069 0xc1006a 0xce0061 0x450074 0xc50085 0x800071 0xd0000f 0xd6007d 0x950066 0xdd0068 0x8c006d 0x890083 0x9c0082 0x9a0078 0xcd0079>;
			phandle = <0x2e>;
		};
	};

	serial@ffd24000 {
		compatible = "amlogic, meson-uart";
		reg = <0xffd24000 0x18>;
		interrupts = <0x00 0x1a 0x01>;
		status = "okay";
		clocks = <0x14 0x02 0x2e>;
		clock-names = "clk_uart\0clk_gate";
		fifosize = <0x80>;
		pinctrl-names = "default";
		pinctrl-0 = <0x2f>;
		phandle = <0xea>;
	};

	serial@ffd23000 {
		compatible = "amlogic, meson-uart";
		reg = <0xffd23000 0x18>;
		interrupts = <0x00 0x4b 0x01>;
		status = "disabled";
		clocks = <0x14 0x02 0x3c>;
		clock-names = "clk_uart\0clk_gate";
		fifosize = <0x40>;
		pinctrl-names = "default";
		pinctrl-0 = <0x30>;
		phandle = <0xeb>;
	};

	serial@ffd22000 {
		compatible = "amlogic, meson-uart";
		reg = <0xffd22000 0x18>;
		interrupts = <0x00 0x5d 0x01>;
		status = "disabled";
		clocks = <0x14 0x02 0x3c>;
		clock-names = "clk_uart\0clk_gate";
		fifosize = <0x40>;
		pinctrl-names = "default";
		pinctrl-0 = <0x31>;
		phandle = <0xec>;
	};

	pcieA@fc000000 {
		compatible = "amlogic, amlogic-pcie-v2\0snps,dw-pcie";
		reg = <0xfc000000 0x400000 0xff648000 0x2000 0xfc400000 0x200000 0xff646000 0x2000 0xffd01080 0x10>;
		reg-names = "elbi\0cfg\0config\0phy\0reset";
		interrupts = <0x00 0xdd 0x00>;
		#interrupt-cells = <0x01>;
		bus-range = <0x00 0xff>;
		#address-cells = <0x03>;
		#size-cells = <0x02>;
		interrupt-map-mask = <0x00 0x00 0x00 0x00>;
		interrupt-map = <0x00 0x00 0x00 0x00 0x01 0x00 0xdf 0x01>;
		device_type = "pci";
		ranges = <0x81000000 0x00 0x00 0xfc600000 0x00 0x100000 0x82000000 0xfc700000 0x00 0xfc700000 0x00 0x1900000>;
		num-lanes = <0x01>;
		pcie-num = <0x01>;
		clocks = <0x02 0x18 0x02 0x3f 0x02 0x42>;
		clock-names = "pcie_refpll\0pcie\0pcie_phy";
		gpio-type = <0x02>;
		pcie-apb-rst-bit = <0x0f>;
		pcie-phy-rst-bit = <0x0e>;
		pcie-ctrl-a-rst-bit = <0x0c>;
		pwr-ctl = <0x01>;
		pcie-ctrl-sleep-shift = <0x12>;
		pcie-hhi-mem-pd-shift = <0x1a>;
		pcie-hhi-mem-pd-mask = <0x0f>;
		pcie-ctrl-iso-shift = <0x12>;
		status = "disable";
		reset-gpio = <0x18 0x49 0x00>;
		phandle = <0xed>;
	};

	amhdmitx {
		compatible = "amlogic, amhdmitx";
		dev_name = "amhdmitx";
		status = "okay";
		vend-data = <0x32>;
		pinctrl-names = "default\0hdmitx_i2c";
		pinctrl-0 = <0x33 0x34>;
		pinctrl-1 = <0x35 0x36>;
		clocks = <0x02 0x55 0x02 0x4e 0x02 0x4f 0x02 0x95 0x02 0x8c>;
		clock-names = "venci_top_gate\0venci_0_gate\0venci_1_gate\0hdmi_vapb_clk\0hdmi_vpu_clk";
		interrupts = <0x00 0x39 0x01>;
		interrupt-names = "hdmitx_hpd";
		ic_type = <0x0c>;
		phandle = <0xee>;

		vend_data {
			vendor_name = "Amlogic";
			product_desc = "MBox Meson Ref";
			vendor_id = <0x00>;
			phandle = <0x32>;
		};
	};

	galcore {
		compatible = "amlogic, galcore";
		dev_name = "galcore";
		status = "okay";
		clocks = <0x02 0xe8 0x02 0xe7>;
		clock-names = "cts_vipnanoq_axi_clk_composite\0cts_vipnanoq_core_clk_composite";
		interrupts = <0x00 0xba 0x04>;
		interrupt-names = "galcore";
		reg = <0xff100000 0x800 0xff000000 0x400000 0xff63c118 0x00 0xff63c11c 0x00 0xffd01088 0x00>;
		nn_efuse = <0xff63003c 0x20>;
	};

	aocec {
		compatible = "amlogic, aocec-sm1";
		device_name = "aocec";
		status = "okay";
		vendor_name = "Amlogic";
		vendor_id = <0x00>;
		product_desc = "SM1";
		cec_osd_string = "AML_MBOX";
		cec_version = <0x05>;
		port_num = <0x01>;
		ee_cec;
		arc_port_mask = <0x02>;
		interrupts = <0x00 0xcb 0x01 0x00 0xc7 0x01>;
		interrupt-names = "hdmi_aocecb\0hdmi_aocec";
		pinctrl-names = "default\0hdmitx_aocecb\0cec_pin_sleep";
		pinctrl-0 = <0x37>;
		pinctrl-1 = <0x38>;
		pinctrl-2 = <0x38>;
		reg = <0xff80023c 0x04 0xff800000 0x400 0xff634400 0x70>;
		reg-names = "ao_exit\0ao\0periphs";
		phandle = <0xef>;
	};

	vdin0 {
		compatible = "amlogic, vdin";
		dev_name = "vdin0";
		status = "okay";
		reserve-iomap = "true";
		flag_cma = <0x00>;
		interrupts = <0x00 0x53 0x01>;
		rdma-irq = <0x02>;
		vdin_id = <0x00>;
		memory-region = <0x39>;
		tv_bit_mode = <0x15>;
		phandle = <0xf0>;
	};

	vdin1 {
		compatible = "amlogic, vdin";
		dev_name = "vdin1";
		status = "okay";
		reserve-iomap = "true";
		flag_cma = <0x00>;
		interrupts = <0x00 0x55 0x01>;
		rdma-irq = <0x04>;
		vdin_id = <0x01>;
		memory-region = <0x3a>;
		tv_bit_mode = <0x01>;
		phandle = <0xf1>;
	};

	vout {
		compatible = "amlogic, vout";
		dev_name = "vout";
		status = "okay";
	};

	vout2 {
		compatible = "amlogic, vout2";
		dev_name = "vout";
		status = "okay";
		clocks = <0x02 0xc4 0x02 0xc9>;
		clock-names = "vpu_clkc0\0vpu_clkc";
	};

	vdac {
		compatible = "amlogic, vdac-sm1";
		status = "okay";
	};

	canvas {
		compatible = "amlogic, meson, canvas";
		dev_name = "amlogic-canvas";
		status = "okay";
		reg = <0xff638000 0x2000>;
		phandle = <0xf2>;
	};

	ge2d {
		compatible = "amlogic, ge2d-sm1";
		dev_name = "ge2d";
		status = "okay";
		interrupts = <0x00 0x92 0x01>;
		interrupt-names = "ge2d";
		clocks = <0x02 0x95 0x02 0x3d 0x02 0x96>;
		clock-names = "clk_vapb_0\0clk_ge2d\0clk_ge2d_gate";
		reg = <0xff940000 0x10000>;
	};

	meson-amvideom {
		compatible = "amlogic, amvideom";
		dev_name = "amvideom";
		status = "okay";
		interrupts = <0x00 0x03 0x01>;
		interrupt-names = "vsync";
	};

	codec_io {
		compatible = "amlogic, codec_io";
		status = "okay";
		#address-cells = <0x01>;
		#size-cells = <0x01>;
		ranges;
		phandle = <0xf3>;

		io_cbus_base {
			reg = <0xffd00000 0x100000>;
		};

		io_dos_base {
			reg = <0xff620000 0x10000>;
		};

		io_hiubus_base {
			reg = <0xff63c000 0x2000>;
		};

		io_aobus_base {
			reg = <0xff800000 0x10000>;
		};

		io_vcbus_base {
			reg = <0xff900000 0x40000>;
		};

		io_dmc_base {
			reg = <0xff638000 0x2000>;
		};

		io_efuse_base {
			reg = <0xff630000 0x2000>;
		};
	};

	mesonstream {
		compatible = "amlogic, codec, streambuf";
		dev_name = "mesonstream";
		status = "okay";
		clocks = <0x02 0x40 0x02 0x39 0x02 0x43 0x02 0x22 0x02 0x0b 0x02 0xa5 0x02 0xae 0x02 0xb7 0x02 0xc0>;
		clock-names = "parser_top\0demux\0ahbarb0\0vdec\0clk_81\0clk_vdec_mux\0clk_hcodec_mux\0clk_hevc_mux\0clk_hevcb_mux";
	};

	vdec {
		compatible = "amlogic, vdec";
		dev_name = "vdec.0";
		status = "okay";
		interrupts = <0x00 0x03 0x01 0x00 0x17 0x01 0x00 0x20 0x01 0x00 0x2b 0x01 0x00 0x2c 0x01 0x00 0x2d 0x01>;
		interrupt-names = "vsync\0demux\0parser\0mailbox_0\0mailbox_1\0mailbox_2";
	};

	vcodec_dec {
		compatible = "amlogic, vcodec-dec";
		dev_name = "aml-vcodec-dec";
		status = "okay";
	};

	amvenc_avc {
		compatible = "amlogic, amvenc_avc";
		dev_name = "amvenc_avc";
		status = "okay";
		interrupts = <0x00 0x2d 0x01>;
		interrupt-names = "mailbox_2";
	};

	hevc_enc {
		compatible = "cnm, HevcEnc";
		dev_name = "HevcEnc";
		status = "okay";
		interrupts = <0x00 0xbb 0x01>;
		interrupt-names = "wave420l_irq";
		#address-cells = <0x01>;
		#size-cells = <0x01>;
		ranges;

		io_reg_base {
			reg = <0xff610000 0x4000>;
		};
	};

	rdma {
		compatible = "amlogic, meson, rdma";
		dev_name = "amlogic-rdma";
		status = "okay";
		interrupts = <0x00 0x59 0x01>;
		interrupt-names = "rdma";
	};

	fb {
		compatible = "amlogic, meson-sm1";
		memory-region = <0x3b>;
		dev_name = "meson-fb";
		status = "okay";
		interrupts = <0x00 0x03 0x01 0x00 0x38 0x01 0x00 0x59 0x01>;
		interrupt-names = "viu-vsync\0viu2-vsync\0rdma";
		display_mode_default = "1080p60hz";
		scale_mode = <0x01>;
		display_size_default = <0x780 0x438 0x780 0x870 0x20>;
		clocks = <0x02 0xc9>;
		clock-names = "vpu_clkc";
		mem_size = <0x800000 0x1980000 0x100000 0x100000 0x800000>;
		logo_addr = "0xdf800000";
		mem_alloc = <0x00>;
		pxp_mode = <0x00>;
		phandle = <0xf4>;
	};

	meson-irblaster {
		compatible = "amlogic, meson_irblaster";
		reg = <0xff80014c 0x10 0xff800040 0x04>;
		pinctrl-names = "default";
		pinctrl-0 = <0x3c>;
		interrupts = <0x00 0xc6 0x01>;
		status = "okay";
		phandle = <0xf5>;
	};

	emmc@ffe07000 {
		status = "okay";
		compatible = "amlogic, meson-mmc-sm1";
		reg = <0xffe07000 0x800>;
		interrupts = <0x00 0xbf 0x01>;
		pinctrl-names = "emmc_clk_cmd_pins\0emmc_all_pins";
		pinctrl-0 = <0x3d>;
		pinctrl-1 = <0x3e 0x3f>;
		clocks = <0x02 0x35 0x02 0x72 0x02 0x02 0x02 0x20 0x14>;
		clock-names = "core\0clkin0\0clkin1\0clkin2\0xtal";
		bus-width = <0x08>;
		cap-sd-highspeed;
		cap-mmc-highspeed;
		max-frequency = <0xbebc200>;
		non-removable;
		disable-wp;
		phandle = <0xf6>;

		emmc {
			pinname = "emmc";
			ocr_avail = <0x200080>;
			tx_delay = <0x00>;
			co_phase = <0x03>;
			max_req_size = <0x20000>;
			gpio_dat3 = <0x18 0x1d 0x00>;
			hw_reset = <0x18 0x26 0x00>;
			card_type = <0x01>;
			caps = "MMC_CAP_8_BIT_DATA\0MMC_CAP_MMC_HIGHSPEED\0MMC_CAP_SD_HIGHSPEED\0MMC_CAP_NONREMOVABLE\0MMC_CAP_HW_RESET\0MMC_CAP_ERASE\0MMC_CAP_CMD23\0MMC_CAP_DRIVER_TYPE_D";
			caps2 = "MMC_CAP2_HS200";
			f_min = <0x61a80>;
			f_max = <0xbebc200>;
		};
	};

	sd@ffe05000 {
		status = "okay";
		compatible = "amlogic, meson-mmc-sm1";
		reg = <0xffe05000 0x800>;
		interrupts = <0x00 0xbe 0x01>;
		pinctrl-names = "sd_all_pins\0sd_clk_cmd_pins\0sd_1bit_pins\0sd_clk_cmd_uart_pins\0sd_1bit_uart_pins\0sd_to_ao_uart_pins\0ao_to_sd_uart_pins\0sd_to_ao_jtag_pins\0ao_to_sd_jtag_pins";
		pinctrl-0 = <0x40>;
		pinctrl-1 = <0x41>;
		pinctrl-2 = <0x42>;
		pinctrl-3 = <0x43 0x41 0x44>;
		pinctrl-4 = <0x43 0x42 0x44>;
		pinctrl-5 = <0x40 0x45>;
		pinctrl-6 = <0x43 0x44>;
		pinctrl-7 = <0x40 0x45>;
		pinctrl-8 = <0x43 0x44>;
		clocks = <0x02 0x34 0x02 0x6e 0x02 0x02 0x02 0x05 0x14>;
		clock-names = "core\0clkin0\0clkin1\0clkin2\0xtal";
		bus-width = <0x04>;
		cap-sd-highspeed;
		cap-mmc-highspeed;
		max-frequency = <0x5f5e100>;
		disable-wp;
		phandle = <0xf7>;

		sd {
			pinname = "sd";
			ocr_avail = <0x200080>;
			max_req_size = <0x20000>;
			gpio_dat3 = <0x18 0x2d 0x00>;
			jtag_pin = <0x18 0x2a 0x00>;
			gpio_cd = <0x18 0x30 0x00>;
			card_type = <0x05>;
			caps = "MMC_CAP_4_BIT_DATA\0MMC_CAP_MMC_HIGHSPEED\0MMC_CAP_SD_HIGHSPEED";
			f_min = <0x61a80>;
			f_max = <0x2faf080>;
		};
	};

	sdio@ffe03000 {
		status = "okay";
		compatible = "amlogic, meson-mmc-sm1";
		reg = <0xffe03000 0x800>;
		interrupts = <0x00 0xbd 0x04>;
		pinctrl-names = "sdio_all_pins\0sdio_clk_cmd_pins";
		pinctrl-0 = <0x46>;
		pinctrl-1 = <0x47>;
		clocks = <0x02 0x33 0x02 0x6a 0x02 0x02 0x02 0x05 0x14>;
		clock-names = "core\0clkin0\0clkin1\0clkin2\0xtal";
		bus-width = <0x04>;
		cap-sd-highspeed;
		cap-mmc-highspeed;
		max-frequency = <0x5f5e100>;
		disable-wp;
		phandle = <0xf8>;

		sdio {
			pinname = "sdio";
			ocr_avail = <0x200080>;
			max_req_size = <0x20000>;
			card_type = <0x03>;
			caps = "MMC_CAP_4_BIT_DATA\0MMC_CAP_MMC_HIGHSPEED\0MMC_CAP_SD_HIGHSPEED\0MMC_CAP_NONREMOVABLE\0MMC_CAP_UHS_SDR12\0MMC_CAP_UHS_SDR25\0MMC_CAP_UHS_SDR50\0MMC_CAP_UHS_SDR104\0MMC_PM_KEEP_POWER\0MMC_CAP_SDIO_IRQ";
			f_min = <0x61a80>;
			f_max = <0xa21fe80>;
		};
	};

	nfc@0 {
		compatible = "amlogic, aml_mtd_nand";
		dev_name = "mtdnand";
		status = "disabled";
		reg = <0xffe07800 0x200>;
		interrupts = <0x00 0x22 0x01>;
		pinctrl-names = "nand_rb_mod\0nand_norb_mod\0nand_cs_only";
		pinctrl-0 = <0x48>;
		pinctrl-1 = <0x48>;
		pinctrl-2 = <0x49>;
		clocks = <0x02 0x35 0x02 0x72>;
		clock-names = "core\0clkin";
		device_id = <0x00>;
		bl_mode = <0x01>;
		fip_copies = <0x04>;
		fip_size = <0x200000>;
		nand_clk_ctrl = <0xffe07000>;
		plat-names = "bootloader\0nandnormal";
		plat-num = <0x02>;
		plat-part-0 = <0x4a>;
		plat-part-1 = <0x4b>;
		phandle = <0xf9>;

		bootloader {
			enable_pad = "ce0";
			busy_pad = "rb0";
			timming_mode = "mode5";
			bch_mode = "bch8_1k";
			t_rea = <0x14>;
			t_rhoh = <0x0f>;
			chip_num = <0x01>;
			part_num = <0x00>;
			rb_detect = <0x01>;
			phandle = <0x4a>;
		};

		nandnormal {
			enable_pad = "ce0";
			busy_pad = "rb0";
			timming_mode = "mode5";
			bch_mode = "bch8_1k";
			plane_mode = "twoplane";
			t_rea = <0x14>;
			t_rhoh = <0x0f>;
			chip_num = <0x02>;
			part_num = <0x03>;
			partition = <0x4c>;
			rb_detect = <0x01>;
			phandle = <0x4b>;
		};

		nand_partition {
			phandle = <0x4c>;

			tpl {
				offset = <0x00 0x00>;
				size = <0x00 0x00>;
			};

			logo {
				offset = <0x00 0x00>;
				size = <0x00 0x200000>;
			};

			recovery {
				offset = <0x00 0x00>;
				size = <0x00 0x1000000>;
			};

			boot {
				offset = <0x00 0x00>;
				size = <0x00 0x1000000>;
			};

			system {
				offset = <0x00 0x00>;
				size = <0x00 0x4000000>;
			};

			data {
				offset = <0xffffffff 0xffffffff>;
				size = <0x00 0x00>;
			};
		};
	};

	aml_snd_iomap {
		compatible = "amlogic, snd-iomap";
		status = "okay";
		#address-cells = <0x01>;
		#size-cells = <0x01>;
		ranges;

		pdm_bus {
			reg = <0xff661000 0x400>;
		};

		audiobus_base {
			reg = <0xff660000 0x1000>;
		};

		audiolocker_base {
			reg = <0xff661400 0x400>;
		};

		eqdrc_base {
			reg = <0xff662000 0x1000>;
		};

		reset_base {
			reg = <0xffd01000 0x1000>;
		};

		vad_base {
			reg = <0xff661800 0x400>;
		};

		earcrx_cdmc_base {
			reg = <0xff663800 0x30>;
		};

		earcrx_dmac_base {
			reg = <0xff663c00 0x20>;
		};

		earcrx_top_base {
			reg = <0xff663e00 0x10>;
		};
	};

	pwmao_d-regulator {
		compatible = "pwm-regulator";
		pwms = <0x4d 0x01 0x4e2 0x00>;
		regulator-name = "vddcpu0";
		regulator-min-microvolt = <0xafc80>;
		regulator-max-microvolt = <0xf9060>;
		regulator-always-on;
		max-duty-cycle = <0x4e2>;
		voltage-table = <0xf9060 0x00 0xf6950 0x03 0xf4240 0x06 0xf1b30 0x0a 0xef420 0x0d 0xecd10 0x10 0xea600 0x14 0xe7ef0 0x17 0xe57e0 0x1a 0xe30d0 0x1e 0xe09c0 0x21 0xde2b0 0x24 0xdbba0 0x28 0xd9490 0x2b 0xd6d80 0x2e 0xd4670 0x32 0xd1f60 0x35 0xcf850 0x38 0xcd140 0x3c 0xcaa30 0x3f 0xc8320 0x43 0xc5c10 0x46 0xc3500 0x49 0xc0df0 0x4c 0xbe6e0 0x50 0xbbfd0 0x53 0xb98c0 0x56 0xb71b0 0x5a 0xb4aa0 0x5d 0xb2390 0x60 0xafc80 0x64>;
		status = "okay";
		phandle = <0x0e>;
	};

	ddr_bandwidth {
		compatible = "amlogic, ddr-bandwidth";
		status = "okay";
		reg = <0xff638000 0x100 0xff638c00 0x100>;
		interrupts = <0x00 0x34 0x01>;
		interrupt-names = "ddr_bandwidth";
	};

	dmc_monitor {
		compatible = "amlogic, dmc_monitor";
		status = "okay";
		reg_base = <0xff639000>;
		interrupts = <0x00 0x33 0x01>;
	};

	defendkey {
		compatible = "amlogic, defendkey";
		reg = <0xff630218 0x04>;
		mem_size = <0x00 0x100000>;
		status = "okay";
		phandle = <0xfa>;
	};

	aml_dma {
		compatible = "amlogic,aml_txlx_dma";
		reg = <0xff63e000 0x48>;
		interrupts = <0x00 0xb4 0x01>;

		aml_aes {
			compatible = "amlogic,aes_g12a_dma";
			dev_name = "aml_aes_dma";
			status = "okay";
		};

		aml_sha {
			compatible = "amlogic,sha_dma";
			dev_name = "aml_sha_dma";
			status = "okay";
		};
	};

	rng {
		compatible = "amlogic,meson-rng";
		status = "okay";
		#address-cells = <0x01>;
		#size-cells = <0x01>;
		reg = <0xff630218 0x04>;
		quality = [03 e8];
	};

	efuse {
		compatible = "amlogic, efuse";
		read_cmd = <0x82000030>;
		write_cmd = <0x82000031>;
		get_max_cmd = <0x82000033>;
		key = <0x4e>;
		clocks = <0x02 0x61>;
		clock-names = "efuse_clk";
		status = "disabled";
		phandle = <0xfb>;
	};

	cpu_ver_name {
		compatible = "amlogic, cpu-major-id-sm1";
	};

	firmware {

		android {
			compatible = "android,firmware";

			vbmeta {
				compatible = "android,vbmeta";
				parts = "vbmeta,boot,system,vendor";
				by_name_prefix = "/dev/block";
			};

			fstab {
				compatible = "android,fstab";

				vendor {
					compatible = "android,vendor";
					dev = "/dev/block/vendor";
					type = "ext4";
					mnt_flags = "ro,barrier=1,inode_readahead_blks=8";
					fsmgr_flags = "wait";
				};

				product {
					compatible = "android,product";
					dev = "/dev/block/product";
					type = "ext4";
					mnt_flags = "ro,barrier=1,inode_readahead_blks=8";
					fsmgr_flags = "wait";
				};

				odm {
					compatible = "android,odm";
					dev = "/dev/block/odm";
					type = "ext4";
					mnt_flags = "ro,barrier=1,inode_readahead_blks=8";
					fsmgr_flags = "wait";
				};
			};
		};
	};

	partitions {
		parts = <0x11>;
		part-0 = <0x4f>;
		part-1 = <0x50>;
		part-2 = <0x51>;
		part-3 = <0x52>;
		part-4 = <0x53>;
		part-5 = <0x54>;
		part-6 = <0x55>;
		part-7 = <0x56>;
		part-8 = <0x57>;
		part-9 = <0x58>;
		part-10 = <0x59>;
		part-11 = <0x5a>;
		part-12 = <0x5b>;
		part-13 = <0x5c>;
		part-14 = <0x5d>;
		part-15 = <0x5e>;
		part-16 = <0x5f>;
		phandle = <0xfc>;

		logo {
			pname = "logo";
			size = <0x00 0x800000>;
			mask = <0x01>;
			phandle = <0x4f>;
		};

		recovery {
			pname = "recovery";
			size = <0x00 0x1800000>;
			mask = <0x01>;
			phandle = <0x50>;
		};

		misc {
			pname = "misc";
			size = <0x00 0x800000>;
			mask = <0x01>;
			phandle = <0x51>;
		};

		dtbo {
			pname = "dtbo";
			size = <0x00 0x800000>;
			mask = <0x01>;
			phandle = <0x52>;
		};

		cri_data {
			pname = "cri_data";
			size = <0x00 0x800000>;
			mask = <0x02>;
			phandle = <0x53>;
		};

		rsv {
			pname = "rsv";
			size = <0x00 0x1000000>;
			mask = <0x01>;
			phandle = <0x56>;
		};

		metadata {
			pname = "metadata";
			size = <0x00 0x1000000>;
			mask = <0x01>;
			phandle = <0x57>;
		};

		vbmeta {
			pname = "vbmeta";
			size = <0x00 0x200000>;
			mask = <0x01>;
			phandle = <0x58>;
		};

		param {
			pname = "param";
			size = <0x00 0x1000000>;
			mask = <0x02>;
			phandle = <0x54>;
		};

		boot {
			pname = "boot";
			size = <0x00 0x1000000>;
			mask = <0x01>;
			phandle = <0x55>;
		};

		tee {
			pname = "tee";
			size = <0x00 0x2000000>;
			mask = <0x01>;
			phandle = <0x59>;
		};

		vendor {
			pname = "vendor";
			size = <0x00 0x46000000>;
			mask = <0x01>;
			phandle = <0x5a>;
		};

		odm {
			pname = "odm";
			size = <0x00 0x8000000>;
			mask = <0x01>;
			phandle = <0x5b>;
		};

		system {
			pname = "system";
			size = <0x00 0x50000000>;
			mask = <0x01>;
			phandle = <0x5c>;
		};

		product {
			pname = "product";
			size = <0x00 0x8000000>;
			mask = <0x01>;
			phandle = <0x5d>;
		};

		cache {
			pname = "cache";
			size = <0x00 0x46000000>;
			mask = <0x02>;
			phandle = <0x5e>;
		};

		data {
			pname = "data";
			size = <0xffffffff 0xffffffff>;
			mask = <0x04>;
			phandle = <0x5f>;
		};
	};

	lcd {
		compatible = "amlogic, lcd-sm1";
		dev_name = "lcd";
		mode = "tablet";
		status = "okay";
		key_valid = <0x00>;
		clocks = <0x02 0x24 0x02 0x31 0x02 0x9a 0x02 0x5d 0x02 0x5f 0x02 0x07>;
		clock-names = "dsi_host_gate\0dsi_phy_gate\0dsi_meas\0encl_top_gate\0encl_int_gate\0gp0_pll";
		reg = <0xffd07000 0x400 0xff644000 0x200>;
		interrupts = <0x00 0x03 0x01 0x00 0x38 0x01>;
		interrupt-names = "vsync\0vsync2";
		pinctrl_version = <0x02>;
		lcd_cpu-gpios = <0x18 0x15 0x00 0x18 0x18 0x00>;
		lcd_cpu_gpio_names = "GPIOH_4\0GPIOH_7";
		phandle = <0xfd>;

		lcd_0 {
			model_name = "B080XAN01";
			interface = "mipi";
			basic_setting = <0x300 0x400 0x3b4 0x474 0x08 0x77 0x9f>;
			lcd_timing = <0x40 0x38 0x00 0x32 0x1e 0x00>;
			clk_attr = <0x00 0x00 0x01 0x3dd6dc0>;
			mipi_attr = <0x04 0x226 0x00 0x01 0x00 0x02 0x01 0x00>;
			dsi_init_on = <0x05 0x01 0x11 0xff 0x14 0x05 0x01 0x29 0xff 0x14 0xff 0xff>;
			dsi_init_off = <0x05 0x01 0x28 0xff 0x0a 0x05 0x01 0x10 0xff 0x0a 0xff 0xff>;
			extern_init = <0xff>;
			power_on_step = <0x00 0x01 0x00 0x64 0x00 0x00 0x00 0x0a 0x00 0x00 0x01 0x14 0x02 0x00 0x00 0x00 0xff 0x00 0x00 0x00>;
			power_off_step = <0x02 0x00 0x00 0x32 0x00 0x00 0x00 0x0a 0x00 0x01 0x01 0x64 0xff 0x00 0x00 0x00>;
			backlight_index = <0x00>;
		};

		lcd_1 {
			model_name = "P070ACB_FT";
			interface = "mipi";
			basic_setting = <0x258 0x400 0x302 0x42e 0x08 0x03 0x05>;
			lcd_timing = <0x0a 0x50 0x00 0x06 0x14 0x00>;
			clk_attr = <0x00 0x00 0x01 0x2f24d90>;
			mipi_attr = <0x04 0x190 0x00 0x01 0x00 0x02 0x00 0x00>;
			dsi_init_on = <0xff 0x0a 0xf0 0x03 0x00 0x01 0x1e 0xf0 0x03 0x00 0x00 0x0a 0xf0 0x03 0x00 0x01 0x1e 0xfc 0x02 0x04 0x03 0xff 0xff>;
			dsi_init_off = <0xff 0xff>;
			extern_init = <0x05>;
			power_on_step = <0x00 0x01 0x00 0xc8 0x02 0x00 0x00 0x00 0xff 0x00 0x00 0x00>;
			power_off_step = <0x02 0x00 0x00 0x00 0x00 0x00 0x00 0x14 0x00 0x01 0x01 0x64 0xff 0x00 0x00 0x00>;
			backlight_index = <0x00>;
		};

		lcd_7 {
			model_name = "EK79007";
			interface = "mipi";
			basic_setting = <0x400 0x258 0x54a 0x27c 0x08 0x77 0x50>;
			lcd_timing = <0x0a 0xa0 0x00 0x01 0x17 0x00>;
			clk_attr = <0x00 0x00 0x01 0x31466a0>;
			mipi_attr = <0x04 0x3e8 0x00 0x01 0x00 0x02 0x01 0x00>;
			dsi_init_on = <0xff 0xff>;
			dsi_init_off = <0xff 0xff>;
			extern_init = <0x06>;
			power_on_step = <0x00 0x00 0x01 0x0a 0x00 0x01 0x00 0x64 0x00 0x00 0x00 0xc8 0x00 0x01 0x01 0x64 0x02 0x00 0x00 0x64 0xff 0x00 0x00 0x00>;
			power_off_step = <0x02 0x00 0x00 0x00 0x00 0x01 0x00 0x64 0x00 0x00 0x01 0x64 0xff 0x00 0x00 0x00>;
			backlight_index = <0x00>;
		};
	};

	lcd_extern {
		compatible = "amlogic, lcd_extern";
		dev_name = "lcd_extern";
		status = "okay";
		i2c_bus = "i2c_bus_0";
		key_valid = <0x00>;

		extern_0 {
			index = <0x00>;
			extern_name = "mipi_default";
			status = "okay";
			type = <0x02>;
			cmd_size = <0xff>;
			init_on = <0xff 0x0a 0x05 0x01 0x11 0xff 0x78 0x05 0x01 0x29 0xff 0xff>;
			init_off = <0x05 0x01 0x28 0xff 0x0a 0x05 0x01 0x10 0xff 0x96 0xff 0xff>;
		};

		extern_1 {
			index = <0x01>;
			extern_name = "mipi_default";
			status = "okay";
			type = <0x02>;
			cmd_size = <0xff>;
			init_on = <0x23 0x02 0xe0 0x00 0x23 0x02 0xe1 0x93 0x23 0x02 0xe2 0x65 0x23 0x02 0xe3 0xf8 0x23 0x02 0x80 0x03 0x23 0x02 0xe0 0x01 0x23 0x02 0x0c 0x74 0x23 0x02 0x17 0x00 0x23 0x02 0x18 0xef 0x23 0x02 0x19 0x00 0x23 0x02 0x1a 0x00 0x23 0x02 0x1b 0xef 0x23 0x02 0x1c 0x00 0x23 0x02 0x1f 0x70 0x23 0x02 0x20 0x2d 0x23 0x02 0x21 0x2d 0x23 0x02 0x22 0x7e 0x23 0x02 0x26 0xf3 0x23 0x02 0x37 0x09 0x23 0x02 0x38 0x04 0x23 0x02 0x39 0x00 0x23 0x02 0x3a 0x01 0x23 0x02 0x3c 0x90 0x23 0x02 0x3d 0xff 0x23 0x02 0x3e 0xff 0x23 0x02 0x3f 0xff 0x23 0x02 0x40 0x02 0x23 0x02 0x41 0x80 0x23 0x02 0x42 0x99 0x23 0x02 0x43 0x14 0x23 0x02 0x44 0x19 0x23 0x02 0x45 0x5a 0x23 0x02 0x4b 0x04 0x23 0x02 0x55 0x02 0x23 0x02 0x56 0x01 0x23 0x02 0x57 0x69 0x23 0x02 0x58 0x0a 0x23 0x02 0x59 0x0a 0x23 0x02 0x5a 0x2e 0x23 0x02 0x5b 0x19 0x23 0x02 0x5c 0x15 0x23 0x02 0x5d 0x77 0x23 0x02 0x5e 0x56 0x23 0x02 0x5f 0x45 0x23 0x02 0x60 0x38 0x23 0x02 0x61 0x35 0x23 0x02 0x62 0x27 0x23 0x02 0x63 0x2d 0x23 0x02 0x64 0x18 0x23 0x02 0x65 0x33 0x23 0x02 0x66 0x34 0x23 0x02 0x67 0x35 0x23 0x02 0x68 0x56 0x23 0x02 0x69 0x45 0x23 0x02 0x6a 0x4f 0x23 0x02 0x6b 0x42 0x23 0x02 0x6c 0x40 0x23 0x02 0x6d 0x34 0x23 0x02 0x6e 0x25 0x23 0x02 0x6f 0x02 0x23 0x02 0x70 0x77 0x23 0x02 0x71 0x56 0x23 0x02 0x72 0x45 0x23 0x02 0x73 0x38 0x23 0x02 0x74 0x35 0x23 0x02 0x75 0x27 0x23 0x02 0x76 0x2d 0x23 0x02 0x77 0x18 0x23 0x02 0x78 0x33 0x23 0x02 0x79 0x34 0x23 0x02 0x7a 0x35 0x23 0x02 0x7b 0x56 0x23 0x02 0x7c 0x45 0x23 0x02 0x7d 0x4f 0x23 0x02 0x7e 0x42 0x23 0x02 0x7f 0x40 0x23 0x02 0x80 0x34 0x23 0x02 0x81 0x25 0x23 0x02 0x82 0x02 0x23 0x02 0xe0 0x02 0x23 0x02 0x00 0x53 0x23 0x02 0x01 0x55 0x23 0x02 0x02 0x55 0x23 0x02 0x03 0x51 0x23 0x02 0x04 0x77 0x23 0x02 0x05 0x57 0x23 0x02 0x06 0x1f 0x23 0x02 0x07 0x4f 0x23 0x02 0x08 0x4d 0x23 0x02 0x09 0x1f 0x23 0x02 0x0a 0x4b 0x23 0x02 0x0b 0x49 0x23 0x02 0x0c 0x1f 0x23 0x02 0x0d 0x47 0x23 0x02 0x0e 0x45 0x23 0x02 0x0f 0x41 0x23 0x02 0x10 0x1f 0x23 0x02 0x11 0x1f 0x23 0x02 0x12 0x1f 0x23 0x02 0x13 0x55 0x23 0x02 0x14 0x1f 0x23 0x02 0x15 0x1f 0x23 0x02 0x16 0x52 0x23 0x02 0x17 0x55 0x23 0x02 0x18 0x55 0x23 0x02 0x19 0x50 0x23 0x02 0x1a 0x77 0x23 0x02 0x1b 0x57 0x23 0x02 0x1c 0x1f 0x23 0x02 0x1d 0x4e 0x23 0x02 0x1e 0x4c 0x23 0x02 0x1f 0x1f 0x23 0x02 0x20 0x4a 0x23 0x02 0x21 0x48 0x23 0x02 0x22 0x1f 0x23 0x02 0x23 0x46 0x23 0x02 0x24 0x44 0x23 0x02 0x25 0x40 0x23 0x02 0x26 0x1f 0x23 0x02 0x27 0x1f 0x23 0x02 0x28 0x1f 0x23 0x02 0x29 0x1f 0x23 0x02 0x2a 0x1f 0x23 0x02 0x2b 0x55 0x23 0x02 0x2c 0x12 0x23 0x02 0x2d 0x15 0x23 0x02 0x2e 0x15 0x23 0x02 0x2f 0x00 0x23 0x02 0x30 0x37 0x23 0x02 0x31 0x17 0x23 0x02 0x32 0x1f 0x23 0x02 0x33 0x08 0x23 0x02 0x34 0x0a 0x23 0x02 0x35 0x1f 0x23 0x02 0x36 0x0c 0x23 0x02 0x37 0x0e 0x23 0x02 0x38 0x1f 0x23 0x02 0x39 0x04 0x23 0x02 0x3a 0x06 0x23 0x02 0x3b 0x10 0x23 0x02 0x3c 0x1f 0x23 0x02 0x3d 0x1f 0x23 0x02 0x3e 0x1f 0x23 0x02 0x3f 0x15 0x23 0x02 0x40 0x1f 0x23 0x02 0x41 0x1f 0x23 0x02 0x42 0x13 0x23 0x02 0x43 0x15 0x23 0x02 0x44 0x15 0x23 0x02 0x45 0x01 0x23 0x02 0x46 0x37 0x23 0x02 0x47 0x17 0x23 0x02 0x48 0x1f 0x23 0x02 0x49 0x09 0x23 0x02 0x4a 0x0b 0x23 0x02 0x4b 0x1f 0x23 0x02 0x4c 0x0d 0x23 0x02 0x4d 0x0f 0x23 0x02 0x4e 0x1f 0x23 0x02 0x4f 0x05 0x23 0x02 0x50 0x07 0x23 0x02 0x51 0x11 0x23 0x02 0x52 0x1f 0x23 0x02 0x53 0x1f 0x23 0x02 0x54 0x1f 0x23 0x02 0x55 0x1f 0x23 0x02 0x56 0x1f 0x23 0x02 0x57 0x15 0x23 0x02 0x58 0x40 0x23 0x02 0x59 0x00 0x23 0x02 0x5a 0x00 0x23 0x02 0x5b 0x10 0x23 0x02 0x5c 0x14 0x23 0x02 0x5d 0x40 0x23 0x02 0x5e 0x01 0x23 0x02 0x5f 0x02 0x23 0x02 0x60 0x40 0x23 0x02 0x61 0x03 0x23 0x02 0x62 0x04 0x23 0x02 0x63 0x7a 0x23 0x02 0x64 0x7a 0x23 0x02 0x65 0x74 0x23 0x02 0x66 0x16 0x23 0x02 0x67 0xb4 0x23 0x02 0x68 0x16 0x23 0x02 0x69 0x7a 0x23 0x02 0x6a 0x7a 0x23 0x02 0x6b 0x0c 0x23 0x02 0x6c 0x00 0x23 0x02 0x6d 0x04 0x23 0x02 0x6e 0x04 0x23 0x02 0x6f 0x88 0x23 0x02 0x70 0x00 0x23 0x02 0x71 0x00 0x23 0x02 0x72 0x06 0x23 0x02 0x73 0x7b 0x23 0x02 0x74 0x00 0x23 0x02 0x75 0xbc 0x23 0x02 0x76 0x00 0x23 0x02 0x77 0x04 0x23 0x02 0x78 0x2c 0x23 0x02 0x79 0x00 0x23 0x02 0x7a 0x00 0x23 0x02 0x7b 0x00 0x23 0x02 0x7c 0x00 0x23 0x02 0x7d 0x03 0x23 0x02 0x7e 0x7b 0x23 0x02 0xe0 0x04 0x23 0x02 0x09 0x11 0x23 0x02 0x0e 0x48 0x23 0x02 0x2b 0x2b 0x23 0x02 0x2e 0x44 0x23 0x02 0xe0 0x00 0x23 0x02 0xe6 0x02 0x23 0x02 0xe7 0x0c 0x05 0x01 0x11 0xff 0x78 0x05 0x01 0x29 0x05 0x01 0x35 0xff 0x14 0xff 0xff>;
			init_off = <0x05 0x01 0x28 0xff 0x0a 0x05 0x01 0x10 0xff 0x96 0xff 0xff>;
		};

		extern_6 {
			index = <0x06>;
			extern_name = "mipi_default";
			status = "okay";
			type = <0x02>;
			cmd_size = <0xff>;
			init_on = <0x15 0x02 0x80 0xac 0x15 0x02 0x81 0xb8 0x15 0x02 0x82 0x09 0x15 0x02 0x83 0x78 0x15 0x02 0x84 0x7f 0x15 0x02 0x85 0xbb 0x15 0x02 0x86 0x70 0xff 0x28 0xff 0xff>;
			init_off = <0xff 0xc8 0xff 0xff>;
		};
	};

	backlight {
		compatible = "amlogic, backlight-sm1";
		dev_name = "backlight";
		status = "okay";
		key_valid = <0x00>;
		pinctrl-names = "pwm_on";
		pinctrl-0 = <0x60>;
		pinctrl_version = <0x02>;
		bl_pwm_config = <0x61>;
		bl-gpios = <0x18 0x16 0x00>;
		bl_gpio_names = "GPIOH_5";

		backlight_0 {
			index = <0x00>;
			bl_name = "backlight_pwm";
			bl_level_default_uboot_kernel = <0x64 0x64>;
			bl_level_attr = <0xff 0x0a 0x80 0x80>;
			bl_ctrl_method = <0x01>;
			bl_pwm_port = "PWM_F";
			bl_pwm_attr = <0x01 0x61a8 0x64 0x19>;
			bl_pwm_power = <0x00 0x00 0x0a 0x0a>;
			bl_pwm_en_sequence_reverse = <0x00>;
		};

		backlight_1 {
			index = <0x01>;
			bl_name = "bl_extern";
			bl_level_default_uboot_kernel = <0x64 0x64>;
			bl_level_attr = <0xff 0x0a 0x80 0x80>;
			bl_ctrl_method = <0x04>;
			bl_power_attr = <0x01 0x01 0x00 0xc8 0xc8>;
			bl_extern_index = <0x00>;
		};
	};

	bl_pwm_conf {
		phandle = <0x61>;

		pwm_channel_0 {
			pwm_port_index = <0x05>;
			pwms = <0x62 0x01 0x7558 0x00>;
		};
	};

	bl_extern {
		compatible = "amlogic, bl_extern";
		dev_name = "bl_extern";
		status = "disabled";
		i2c_bus = "i2c_bus_3";

		extern_0 {
			index = <0x00>;
			extern_name = "i2c_lp8556";
			type = <0x00>;
			i2c_address = <0x2c>;
			dim_max_min = <0xff 0x0a>;
		};

		extern_1 {
			index = <0x01>;
			extern_name = "mipi_lt070me05";
			type = <0x02>;
			dim_max_min = <0xff 0x0a>;
		};
	};

	aliases {
		serial0 = "/soc/aobus@ff800000/serial@3000";
		serial1 = "/serial@ffd24000";
		serial2 = "/serial@ffd23000";
		serial3 = "/serial@ffd22000";
		serial4 = "/soc/aobus@ff800000/serial@4000";
		tsensor0 = "/p_tsensor@ff634594";
		tsensor1 = "/d_tsensor@ff800228";
		i2c0 = "/soc/cbus@ffd00000/i2c@1f000";
		i2c1 = "/soc/cbus@ffd00000/i2c@1e000";
		i2c2 = "/soc/cbus@ffd00000/i2c@1d000";
		i2c3 = "/soc/cbus@ffd00000/i2c@1c000";
		i2c4 = "/soc/aobus@ff800000/i2c@5000";
	};

	memory@00000000 {
		device_type = "memory";
		linux,usable-memory = <0x100000 0xf0800000>;
	};

	reserved-memory {
		#address-cells = <0x01>;
		#size-cells = <0x01>;
		ranges;

		ramoops@0x07400000 {
			compatible = "ramoops";
			reg = <0x7400000 0x100000>;
			record-size = <0x8000>;
			console-size = <0x8000>;
			ftrace-size = <0x40000>;
		};

		linux,secmon {
			compatible = "shared-dma-pool";
			reusable;
			size = <0x400000>;
			alignment = <0x400000>;
			alloc-ranges = <0x5000000 0x400000>;
			phandle = <0x0f>;
		};

		linux,secos {
			status = "disable";
			compatible = "amlogic, aml_secos_memory";
			reg = <0x5300000 0x2000000>;
			no-map;
			phandle = <0xfe>;
		};

		linux,meson-fb {
			compatible = "shared-dma-pool";
			reusable;
			size = <0x800000>;
			alignment = <0x400000>;
			alloc-ranges = <0xdf800000 0x800000>;
			phandle = <0x3b>;
		};

		linux,ion-dev {
			compatible = "shared-dma-pool";
			reusable;
			size = <0x8000000>;
			alignment = <0x400000>;
			alloc-ranges = <0x30000000 0x50000000>;
			phandle = <0x1d>;
		};

		linux,di_cma {
			compatible = "shared-dma-pool";
			reusable;
			size = <0x2800000>;
			alignment = <0x400000>;
			phandle = <0x6a>;
		};

		linux,ppmgr {
			compatible = "shared-dma-pool";
			size = <0x00>;
			phandle = <0x69>;
		};

		linux,codec_mm_cma {
			compatible = "shared-dma-pool";
			reusable;
			size = <0x13400000>;
			alignment = <0x400000>;
			linux,contiguous-region;
			alloc-ranges = <0x30000000 0x50000000>;
			phandle = <0x66>;
		};

		linux,codec_mm_reserved {
			compatible = "amlogic, codec-mm-reserved";
			size = <0x00>;
			alignment = <0x100000>;
			phandle = <0x67>;
		};

		linux,vdin0_cma {
			compatible = "shared-dma-pool";
			reusable;
			size = <0x4000000>;
			alignment = <0x400000>;
			phandle = <0x39>;
		};

		linux,vdin1_cma {
			compatible = "shared-dma-pool";
			reusable;
			size = <0x4000000>;
			alignment = <0x400000>;
			phandle = <0x3a>;
		};

		linux,vm0_cma {
			compatible = "shared-dma-pool";
			reusable;
			size = <0x2000000>;
			alignment = <0x400000>;
			phandle = <0xff>;
		};
	};

	dummy-battery {
		compatible = "amlogic, dummy-battery";
		status = "disabled";
		phandle = <0x100>;
	};

	dummy-charger {
		compatible = "amlogic, dummy-charger";
		status = "disabled";
		phandle = <0x101>;
	};

	gpioleds {
		compatible = "gpio-leds";
		status = "okay";

		sys_led {
			label = "sys_led";
			gpios = <0x63 0x0b 0x00>;
			default-state = "on";
		};
	};

	meson-vfd {
		compatible = "amlogic,aml_vfd";
		dev_name = "meson-vfd";
		vfd_data_gpio = <0x18 0x40 0x00>;
		vfd_clock_gpio = <0x18 0x41 0x00>;
		vfd_stb_gpio = <0x63 0x0a 0x00>;
		status = "okay";
		gpios = <0x63 0x0a 0x00 0x18 0x41 0x00 0x18 0x40 0x00>;
		dot_names = "APPS\0SETUP\0USB\0CARD\0:\0HDMI\0CVBS";
		dot_bits = [00 03 01 03 02 03 03 03 04 03 05 03 06 03];
	};

	cvbsout {
		compatible = "amlogic, cvbsout-sm1";
		dev_name = "cvbsout";
		status = "okay";
		clocks = <0x02 0x55 0x02 0x4e 0x02 0x4f 0x02 0x57>;
		clock-names = "venci_top_gate\0venci_0_gate\0venci_1_gate\0vdac_clk_gate";
		clk_path = <0x00>;
		performance = <0x1bf0 0x09 0x1b56 0x333 0x1b12 0x8080 0x1b05 0xfd 0x1c59 0xf850 0xffff 0x00>;
		performance_sarft = <0x1bf0 0x09 0x1b56 0x333 0x1b12 0x00 0x1b05 0x09 0x1c59 0xfc48 0xffff 0x00>;
		performance_revB_telecom = <0x1bf0 0x09 0x1b56 0x546 0x1b12 0x8080 0x1b05 0x09 0x1c59 0xf850 0xffff 0x00>;
	};

	bt-dev {
		compatible = "amlogic, bt-dev";
		dev_name = "bt-dev";
		status = "okay";
		gpio_reset = <0x18 0x53 0x00>;
		gpio_hostwake = <0x18 0x55 0x00>;
	};

	wifi {
		compatible = "amlogic, aml_wifi";
		dev_name = "aml_wifi";
		status = "okay";
		interrupt_pin = <0x18 0x49 0x00>;
		irq_trigger_type = "GPIO_IRQ_LOW";
		power_on_pin = <0x18 0x48 0x00>;
		dhd_static_buf;
		pinctrl-names = "default";
		pinctrl-0 = <0x64>;
		pwm_config = <0x65>;
	};

	wifi_pwm_conf {
		phandle = <0x65>;

		pwm_channel1_conf {
			pwms = <0x62 0x00 0x774d 0x00>;
			duty-cycle = <0x3ba6>;
			times = <0x0a>;
		};

		pwm_channel2_conf {
			pwms = <0x62 0x02 0x7724 0x00>;
			duty-cycle = <0x3b92>;
			times = <0x0c>;
		};
	};

	linux,picdec {
		compatible = "shared-dma-pool";
		reusable;
		size = <0x00>;
		alignment = <0x00>;
		linux,contiguous-region;
		phandle = <0x68>;
	};

	codec_mm {
		compatible = "amlogic, codec, mm";
		memory-region = <0x66 0x67>;
		dev_name = "codec_mm";
		status = "okay";
	};

	picdec {
		compatible = "amlogic, picdec";
		memory-region = <0x68>;
		dev_name = "picdec";
		status = "okay";
	};

	ppmgr {
		compatible = "amlogic, ppmgr";
		memory-region = <0x69>;
		dev_name = "ppmgr";
		status = "okay";
	};

	deinterlace {
		compatible = "amlogic, deinterlace";
		status = "okay";
		flag_cma = <0x01>;
		memory-region = <0x6a>;
		interrupts = <0x00 0x2e 0x01 0x00 0x28 0x01>;
		interrupt-names = "pre_irq\0post_irq";
		clocks = <0x02 0x9b 0x02 0x9c>;
		clock-names = "vpu_clkb_tmp_composite\0vpu_clkb_composite";
		clock-range = <0x14e 0x29b>;
		buffer-size = <0x3e2c40>;
		post-wr-support = <0x01>;
		nr10bit-support = <0x01>;
		nrds-enable = <0x01>;
		pps-enable = <0x01>;
	};

	ionvideo {
		compatible = "amlogic, ionvideo";
		dev_name = "ionvideo";
		status = "okay";
	};

	amlvideo2_0 {
		compatible = "amlogic, amlvideo2";
		dev_name = "amlvideo2";
		status = "okay";
		amlvideo2_id = <0x00>;
		cma_mode = <0x01>;
	};

	amlvideo2_1 {
		compatible = "amlogic, amlvideo2";
		dev_name = "amlvideo2";
		status = "okay";
		amlvideo2_id = <0x01>;
		cma_mode = <0x01>;
	};

	unifykey {
		compatible = "amlogic, unifykey";
		status = "ok";
		unifykey-num = <0x10>;
		unifykey-index-0 = <0x6b>;
		unifykey-index-1 = <0x6c>;
		unifykey-index-2 = <0x6d>;
		unifykey-index-3 = <0x6e>;
		unifykey-index-4 = <0x6f>;
		unifykey-index-5 = <0x70>;
		unifykey-index-6 = <0x71>;
		unifykey-index-7 = <0x72>;
		unifykey-index-8 = <0x73>;
		unifykey-index-9 = <0x74>;
		unifykey-index-10 = <0x75>;
		unifykey-index-11 = <0x76>;
		unifykey-index-12 = <0x77>;
		unifykey-index-13 = <0x78>;
		unifykey-index-14 = <0x79>;
		unifykey-index-15 = <0x7a>;

		key_0 {
			key-name = "usid";
			key-device = "normal";
			key-permit = "read\0write\0del";
			phandle = <0x6b>;
		};

		key_1 {
			key-name = "mac";
			key-device = "normal";
			key-permit = "read\0write\0del";
			phandle = <0x6c>;
		};

		key_2 {
			key-name = "hdcp";
			key-device = "secure";
			key-type = "sha1";
			key-permit = "read\0write\0del";
			phandle = <0x6d>;
		};

		key_3 {
			key-name = "secure_boot_set";
			key-device = "efuse";
			key-permit = "write";
			phandle = <0x6e>;
		};

		key_4 {
			key-name = "mac_bt";
			key-device = "normal";
			key-permit = "read\0write\0del";
			key-type = "mac";
			phandle = <0x6f>;
		};

		key_5 {
			key-name = "mac_wifi";
			key-device = "normal";
			key-permit = "read\0write\0del";
			key-type = "mac";
			phandle = <0x70>;
		};

		key_6 {
			key-name = "hdcp2_tx";
			key-device = "normal";
			key-permit = "read\0write\0del";
			phandle = <0x71>;
		};

		key_7 {
			key-name = "hdcp2_rx";
			key-device = "normal";
			key-permit = "read\0write\0del";
			phandle = <0x72>;
		};

		key_8 {
			key-name = "widevinekeybox";
			key-device = "secure";
			key-permit = "read\0write\0del";
			phandle = <0x73>;
		};

		key_9 {
			key-name = "deviceid";
			key-device = "normal";
			key-permit = "read\0write\0del";
			phandle = <0x74>;
		};

		key_10 {
			key-name = "hdcp22_fw_private";
			key-device = "secure";
			key-permit = "read\0write\0del";
			phandle = <0x75>;
		};

		key_11 {
			key-name = "PlayReadykeybox25";
			key-device = "secure";
			key-permit = "read\0write\0del";
			phandle = <0x76>;
		};

		key_12 {
			key-name = "prpubkeybox";
			key-device = "secure";
			key-permit = "read\0write\0del";
			phandle = <0x77>;
		};

		key_13 {
			key-name = "prprivkeybox";
			key-device = "secure";
			key-permit = "read\0write\0del";
			phandle = <0x78>;
		};

		key_14 {
			key-name = "attestationkeybox";
			key-device = "secure";
			key-permit = "read\0write\0del";
			phandle = <0x79>;
		};

		key_15 {
			key-name = "netflix_mgkid";
			key-device = "secure";
			key-permit = "read\0write\0del";
			phandle = <0x7a>;
		};
	};

	efusekey {
		keynum = <0x04>;
		key0 = <0x7b>;
		key1 = <0x7c>;
		key2 = <0x7d>;
		key3 = <0x7e>;
		phandle = <0x4e>;

		key_0 {
			keyname = "mac";
			offset = <0x00>;
			size = <0x06>;
			phandle = <0x7b>;
		};

		key_1 {
			keyname = "mac_bt";
			offset = <0x06>;
			size = <0x06>;
			phandle = <0x7c>;
		};

		key_2 {
			keyname = "mac_wifi";
			offset = <0x0c>;
			size = <0x06>;
			phandle = <0x7d>;
		};

		key_3 {
			keyname = "usid";
			offset = <0x12>;
			size = <0x10>;
			phandle = <0x7e>;
		};
	};

	amlvecm {
		compatible = "amlogic, vecm";
		dev_name = "aml_vecm";
		status = "okay";
		gamma_en = <0x00>;
		wb_en = <0x00>;
		cm_en = <0x00>;
		tx_op_color_primary = <0x00>;
	};

	amdolby_vision {
		compatible = "amlogic, dolby_vision_sm1";
		dev_name = "aml_amdolby_vision_driver";
		status = "okay";
		tv_mode = <0x00>;
	};

	dummy {
		#sound-dai-cells = <0x00>;
		compatible = "amlogic, aml_dummy_codec";
		status = "okay";
		phandle = <0x80>;
	};

	t9015 {
		#sound-dai-cells = <0x00>;
		compatible = "amlogic, aml_codec_T9015";
		reg = <0xff632000 0x2000>;
		is_auge_used = <0x01>;
		tocodec_inout = <0x01>;
		tdmout_index = <0x01>;
		ch0_sel = <0x00>;
		ch1_sel = <0x01>;
		status = "okay";
		phandle = <0x82>;
	};

	eqdrc {
		eqdrc_module = <0x01>;
		lane_mask = <0x01>;
		channel_mask = <0x03>;
		phandle = <0x102>;
	};

	auge_sound {
		compatible = "amlogic, g12a-sound-card";
		aml-audio-card,name = "AML-AUGESOUND";
		avout_mute-gpios = <0x63 0x02 0x00>;

		aml-audio-card,dai-link@0 {
			format = "dsp_a";
			mclk-fs = <0x200>;
			bitclock-master = <0x7f>;
			frame-master = <0x7f>;
			suffix-name = "alsaPORT-pcm";

			cpu {
				sound-dai = <0x7f>;
				dai-tdm-slot-tx-mask = <0x01 0x01 0x01 0x01 0x01 0x01 0x01 0x01>;
				dai-tdm-slot-rx-mask = <0x01 0x01 0x01 0x01 0x01 0x01 0x01 0x01>;
				dai-tdm-slot-num = <0x08>;
				dai-tdm-slot-width = <0x20>;
				system-clock-frequency = <0x1770000>;
				phandle = <0x103>;
			};

			codec {
				sound-dai = <0x80 0x80>;
				phandle = <0x104>;
			};
		};

		aml-audio-card,dai-link@1 {
			format = "i2s";
			mclk-fs = <0x100>;
			bitclock-master = <0x81>;
			frame-master = <0x81>;
			suffix-name = "alsaPORT-i2s";

			cpu {
				sound-dai = <0x81>;
				dai-tdm-slot-tx-mask = <0x01 0x01>;
				dai-tdm-slot-rx-mask = <0x01 0x01>;
				dai-tdm-slot-num = <0x02>;
				dai-tdm-slot-width = <0x20>;
				system-clock-frequency = <0xbb8000>;
			};

			codec {
				sound-dai = <0x80 0x80 0x82>;
				phandle = <0x105>;
			};
		};

		aml-audio-card,dai-link@2 {
			format = "i2s";
			mclk-fs = <0x100>;
			bitclock-master = <0x83>;
			frame-master = <0x83>;

			cpu {
				sound-dai = <0x83>;
				dai-tdm-slot-tx-mask = <0x01 0x01>;
				dai-tdm-slot-rx-mask = <0x01 0x01>;
				dai-tdm-slot-num = <0x02>;
				dai-tdm-slot-width = <0x20>;
				system-clock-frequency = <0xbb8000>;
			};

			codec {
				sound-dai = <0x80>;
				phandle = <0x106>;
			};
		};

		aml-audio-card,dai-link@3 {
			mclk-fs = <0x40>;
			suffix-name = "alsaPORT-pdm";

			cpu {
				sound-dai = <0x84>;
			};

			codec {
				sound-dai = <0x80>;
			};
		};

		aml-audio-card,dai-link@4 {
			mclk-fs = <0x80>;
			suffix-name = "alsaPORT-spdif";

			cpu {
				sound-dai = <0x85>;
				system-clock-frequency = <0x5dc000>;
			};

			codec {
				sound-dai = <0x80>;
			};
		};

		aml-audio-card,dai-link@5 {
			mclk-fs = <0x80>;
			continuous-clock;
			suffix-name = "alsaPORT-spdifb";

			cpu {
				sound-dai = <0x86>;
				system-clock-frequency = <0x5dc000>;
			};

			codec {
				sound-dai = <0x80>;
			};
		};

		aml-audio-card,dai-link@6 {
			mclk-fs = <0x100>;
			suffix-name = "alsaPORT-earc";

			cpu {
				sound-dai = <0x87>;
				system-clock-frequency = <0xbb8000>;
			};

			codec {
				sound-dai = <0x80>;
			};
		};
	};

	locker {
		compatible = "amlogic, audiolocker";
		clocks = <0x1e 0x2d 0x1e 0x2e 0x1e 0x27 0x1e 0x28 0x02 0x0d 0x02 0x0e>;
		clock-names = "lock_out\0lock_in\0out_src\0in_src\0out_calc\0in_ref";
		interrupts = <0x00 0x01 0x01>;
		interrupt-names = "irq";
		frequency = <0x2ebae40>;
		dividor = <0x31>;
		status = "disabled";
		phandle = <0x107>;
	};

	p_tsensor@ff634594 {
		compatible = "amlogic, r1p1-tsensor";
		device_name = "meson-pthermal";
		status = "okay";
		reg = <0xff634800 0x50 0xff800268 0x04>;
		cal_type = <0x01>;
		cal_a = <0x144>;
		cal_b = <0x1a8>;
		cal_c = <0xc57>;
		cal_d = <0x24c3>;
		rtemp = <0x1c138>;
		interrupts = <0x00 0x23 0x00>;
		clocks = <0x02 0xd6>;
		clock-names = "ts_comp";
		#thermal-sensor-cells = <0x01>;
		phandle = <0x88>;
	};

	d_tsensor@ff800228 {
		compatible = "amlogic, r1p1-tsensor";
		device_name = "meson-dthermal";
		status = "okay";
		reg = <0xff634c00 0x50 0xff800230 0x04>;
		cal_type = <0x01>;
		cal_a = <0x144>;
		cal_b = <0x1a8>;
		cal_c = <0xc57>;
		cal_d = <0x24c3>;
		rtemp = <0x1c138>;
		interrupts = <0x00 0x24 0x00>;
		clocks = <0x02 0xd6>;
		clock-names = "ts_comp";
		#thermal-sensor-cells = <0x01>;
		phandle = <0x8e>;
	};

	meson-cooldev@0 {
		status = "okay";
		compatible = "amlogic, meson-cooldev";
		device_name = "mcooldev";
		phandle = <0x108>;

		cooling_devices {

			cpufreq_cool_cluster0 {
				min_state = <0xf4240>;
				dyn_coeff = <0x7d>;
				cluster_id = <0x00>;
				node_name = "cpufreq_cool0";
				device_type = "cpufreq";
			};

			cpucore_cool_cluster0 {
				min_state = <0x01>;
				dyn_coeff = <0x00>;
				cluster_id = <0x00>;
				node_name = "cpucore_cool0";
				device_type = "cpucore";
			};

			gpufreq_cool {
				min_state = <0x190>;
				dyn_coeff = <0xd7>;
				gpu_pp = <0x02>;
				cluster_id = <0x00>;
				node_name = "gpufreq_cool0";
				device_type = "gpufreq";
			};

			gpucore_cool {
				min_state = <0x01>;
				dyn_coeff = <0x00>;
				cluster_id = <0x00>;
				node_name = "gpucore_cool0";
				device_type = "gpucore";
			};
		};

		cpufreq_cool0 {
			#cooling-cells = <0x02>;
			phandle = <0x8a>;
		};

		cpucore_cool0 {
			#cooling-cells = <0x02>;
			phandle = <0x8b>;
		};

		gpufreq_cool0 {
			#cooling-cells = <0x02>;
			phandle = <0x8c>;
		};

		gpucore_cool0 {
			#cooling-cells = <0x02>;
			phandle = <0x8d>;
		};
	};

	thermal-zones {

		soc_thermal {
			polling-delay = <0x3e8>;
			polling-delay-passive = <0x64>;
			sustainable-power = <0x582>;
			thermal-sensors = <0x88 0x00>;
			phandle = <0x109>;

			trips {

				trip-point@0 {
					temperature = <0xea60>;
					hysteresis = <0x1388>;
					type = "passive";
					phandle = <0x10a>;
				};

				trip-point@1 {
					temperature = <0x124f8>;
					hysteresis = <0x1388>;
					type = "passive";
					phandle = <0x89>;
				};

				trip-point@2 {
					temperature = <0x14c08>;
					hysteresis = <0x1388>;
					type = "hot";
					phandle = <0x10b>;
				};

				trip-point@3 {
					temperature = <0x1adb0>;
					hysteresis = <0x3e8>;
					type = "critical";
					phandle = <0x10c>;
				};
			};

			cooling-maps {

				cpufreq_cooling_map {
					trip = <0x89>;
					cooling-device = <0x8a 0x00 0x04>;
					contribution = <0x400>;
				};

				cpucore_cooling_map {
					trip = <0x89>;
					cooling-device = <0x8b 0x00 0x03>;
					contribution = <0x400>;
				};

				gpufreq_cooling_map {
					trip = <0x89>;
					cooling-device = <0x8c 0x00 0x04>;
					contribution = <0x400>;
				};

				gpucore_cooling_map {
					trip = <0x89>;
					cooling-device = <0x8d 0x00 0x02>;
					contribution = <0x400>;
				};
			};
		};

		ddr_thermal {
			polling-delay = <0x7d0>;
			polling-delay-passive = <0x3e8>;
			sustainable-power = <0x582>;
			thermal-sensors = <0x8e 0x01>;
			phandle = <0x10d>;

			trips {

				trip-point@0 {
					temperature = <0xea60>;
					hysteresis = <0x1388>;
					type = "passive";
					phandle = <0x10e>;
				};

				trip-point@1 {
					temperature = <0x124f8>;
					hysteresis = <0x1388>;
					type = "passive";
					phandle = <0x10f>;
				};

				trip-point@2 {
					temperature = <0x14c08>;
					hysteresis = <0x1388>;
					type = "hot";
					phandle = <0x110>;
				};

				trip-point@3 {
					temperature = <0x1adb0>;
					hysteresis = <0x3e8>;
					type = "critical";
					phandle = <0x111>;
				};
			};
		};
	};

	cpu_opp_table0 {
		compatible = "operating-points-v2";
		opp-shared;
		phandle = <0x0d>;

		opp00 {
			opp-hz = <0x00 0x5f5e100>;
			opp-microvolt = <0xb2390>;
		};

		opp01 {
			opp-hz = <0x00 0xee6b280>;
			opp-microvolt = <0xb2390>;
		};

		opp02 {
			opp-hz = <0x00 0x1dcd6500>;
			opp-microvolt = <0xb2390>;
		};

		opp03 {
			opp-hz = <0x00 0x27c19cc0>;
			opp-microvolt = <0xb2390>;
		};

		opp04 {
			opp-hz = <0x00 0x3b9aca00>;
			opp-microvolt = <0xb4aa0>;
		};

		opp05 {
			opp-hz = <0x00 0x47868c00>;
			opp-microvolt = <0xb71b0>;
		};

		opp06 {
			opp-hz = <0x00 0x53af5700>;
			opp-microvolt = <0xbe6e0>;
		};

		opp07 {
			opp-hz = <0x00 0x59682f00>;
			opp-microvolt = <0xc5c10>;
		};

		opp08 {
			opp-hz = <0x00 0x5fd82200>;
			opp-microvolt = <0xcf850>;
		};

		opp09 {
			opp-hz = <0x00 0x6590fa00>;
			opp-microvolt = <0xdbba0>;
		};

		opp10 {
			opp-hz = <0x00 0x6b49d200>;
			opp-microvolt = <0xe7ef0>;
		};

		opp11 {
			opp-hz = <0x00 0x71b9c500>;
			opp-microvolt = <0xf6950>;
		};
	};

	cpufreq-meson {
		compatible = "amlogic, cpufreq-meson";
		pinctrl-names = "default";
		pinctrl-0 = <0x8f>;
		status = "okay";
	};

	__symbols__ {
		gpu = "/bifrost";
		dvfs125_cfg = "/bifrost/clk125_cfg";
		dvfs250_cfg = "/bifrost/dvfs250_cfg";
		dvfs285_cfg = "/bifrost/dvfs285_cfg";
		dvfs400_cfg = "/bifrost/dvfs400_cfg";
		dvfs500_cfg = "/bifrost/dvfs500_cfg";
		dvfs666_cfg = "/bifrost/dvfs666_cfg";
		dvfs800_cfg = "/bifrost/dvfs800_cfg";
		dvfs850_cfg = "/bifrost/dvfs850_cfg";
		cpus = "/cpus";
		cluster0 = "/cpus/cpu-map/cluster0";
		CPU0 = "/cpus/cpu@0";
		CPU1 = "/cpus/cpu@1";
		CPU2 = "/cpus/cpu@2";
		CPU3 = "/cpus/cpu@3";
		CPU_SLEEP_0 = "/cpus/idle-states/cpu-sleep-0";
		gic = "/interrupt-controller@2c001000";
		mailbox = "/mhu@c883c400";
		xtal = "/xtal-clk";
		vpu = "/vpu";
		ethmac = "/ethernet@ff3f0000";
		pinctrl_aobus = "/pinctrl@ff800014";
		gpio_ao = "/pinctrl@ff800014/ao-bank@ff800014";
		sd_to_ao_uart_clr_pins = "/pinctrl@ff800014/sd_to_ao_uart_clr_pins";
		sd_to_ao_uart_pins = "/pinctrl@ff800014/sd_to_ao_uart_pins";
		ao_uart_pins = "/pinctrl@ff800014/ao_uart";
		ao_b_uart_pins = "/pinctrl@ff800014/ao_b_uart";
		ao_i2c_master_pins1 = "/pinctrl@ff800014/ao_i2c_pins1";
		ao_i2c_master_pins2 = "/pinctrl@ff800014/ao_i2c_pins2";
		ao_i2c_slave_pins = "/pinctrl@ff800014/ao_i2c_slave_pins";
		pwm_ao_a_pins = "/pinctrl@ff800014/pwm_ao_a";
		pwm_ao_a_hiz_pins = "/pinctrl@ff800014/pwm_ao_a_hiz";
		pwm_ao_b_pins = "/pinctrl@ff800014/pwm_ao_b";
		pwm_ao_c_pins1 = "/pinctrl@ff800014/pwm_ao_c_pins1";
		pwm_ao_c_pins2 = "/pinctrl@ff800014/pwm_ao_c_pins2";
		pwm_ao_c_hiz_pins = "/pinctrl@ff800014/pwm_ao_c_hiz";
		pwm_ao_d_pins1 = "/pinctrl@ff800014/pwm_ao_d_pins1";
		pwm_ao_d_pins2 = "/pinctrl@ff800014/pwm_ao_d_pins2";
		pwm_ao_d_pins3 = "/pinctrl@ff800014/pwm_ao_d_pins3";
		aocec_a = "/pinctrl@ff800014/ao_ceca";
		aocec_b = "/pinctrl@ff800014/ao_cecb";
		jtag_apao_pins = "/pinctrl@ff800014/jtag_apao_pin";
		remote_pins = "/pinctrl@ff800014/remote_pin";
		irblaster_pins = "/pinctrl@ff800014/irblaster_pin";
		pinctrl_periphs = "/pinctrl@ff634480";
		gpio = "/pinctrl@ff634480/banks@ff6346c0";
		emmc_clk_cmd_pins = "/pinctrl@ff634480/emmc_clk_cmd_pins";
		emmc_conf_pull_up = "/pinctrl@ff634480/emmc_conf_pull_up";
		emmc_conf_pull_done = "/pinctrl@ff634480/emmc_conf_pull_done";
		sd_clk_cmd_pins = "/pinctrl@ff634480/sd_clk_cmd_pins";
		sd_all_pins = "/pinctrl@ff634480/sd_all_pins";
		sd_1bit_pins = "/pinctrl@ff634480/sd_1bit_pins";
		sd_clr_all_pins = "/pinctrl@ff634480/sd_clr_all_pins";
		sd_clr_noall_pins = "/pinctrl@ff634480/sd_clr_noall_pins";
		ao_to_sd_uart_pins = "/pinctrl@ff634480/ao_to_sd_uart_pins";
		sdio_clk_cmd_pins = "/pinctrl@ff634480/sdio_clk_cmd_pins";
		sdio_all_pins = "/pinctrl@ff634480/sdio_all_pins";
		sdio_x_clk_cmd_pins = "/pinctrl@ff634480/sdio_x_clk_cmd_pins";
		sdio_x_all_pins = "/pinctrl@ff634480/sdio_x_all_pins";
		sdio_x_en_pins = "/pinctrl@ff634480/sdio_x_en_pins";
		sdio_x_clr_pins = "/pinctrl@ff634480/sdio_x_clr_pins";
		all_nand_pins = "/pinctrl@ff634480/all_nand_pins";
		nand_cs_pins = "/pinctrl@ff634480/nand_cs";
		i2c0_master_pins1 = "/pinctrl@ff634480/i2c0_pins1";
		i2c0_master_pins2 = "/pinctrl@ff634480/i2c0_pins2";
		i2c0_master_pins3 = "/pinctrl@ff634480/i2c0_pins3";
		i2c1_master_pins1 = "/pinctrl@ff634480/i2c1_pins1";
		i2c1_master_pins2 = "/pinctrl@ff634480/i2c1_pins2";
		i2c1_master_pins3 = "/pinctrl@ff634480/i2c1_pins3";
		i2c2_master_pins1 = "/pinctrl@ff634480/i2c2_pins1";
		i2c2_master_pins2 = "/pinctrl@ff634480/i2c2_pins2";
		i2c2_master_pins3 = "/pinctrl@ff634480/i2c2_pins3";
		i2c3_master_pins1 = "/pinctrl@ff634480/i2c3_pins1";
		i2c3_master_pins2 = "/pinctrl@ff634480/i2c3_pins2";
		pwm_a_pins = "/pinctrl@ff634480/pwm_a";
		pwm_b_pins1 = "/pinctrl@ff634480/pwm_b_pins1";
		pwm_b_pins2 = "/pinctrl@ff634480/pwm_b_pins2";
		pwm_c_pins1 = "/pinctrl@ff634480/pwm_c_pins1";
		pwm_c_pins2 = "/pinctrl@ff634480/pwm_c_pins2";
		pwm_c_pins3 = "/pinctrl@ff634480/pwm_c_pins3";
		pwm_d_pins1 = "/pinctrl@ff634480/pwm_d_pins1";
		pwm_d_pins2 = "/pinctrl@ff634480/pwm_d_pins2";
		pwm_e_pins = "/pinctrl@ff634480/pwm_e";
		pwm_f_pins1 = "/pinctrl@ff634480/pwm_f_pins1";
		pwm_f_pins2 = "/pinctrl@ff634480/pwm_f_pins2";
		spicc0_pins_x = "/pinctrl@ff634480/spicc0_pins_x";
		spicc0_pins_c = "/pinctrl@ff634480/spicc0_pins_c";
		spicc1_pins = "/pinctrl@ff634480/spicc1_pins";
		a_uart_pins = "/pinctrl@ff634480/a_uart";
		b_uart_pins = "/pinctrl@ff634480/b_uart";
		c_uart_pins = "/pinctrl@ff634480/c_uart";
		hdmitx_hpd = "/pinctrl@ff634480/hdmitx_hpd";
		hdmitx_hpd_gpio = "/pinctrl@ff634480/hdmitx_hpd_gpio";
		hdmitx_ddc = "/pinctrl@ff634480/hdmitx_ddc";
		eecec_a = "/pinctrl@ff634480/ee_ceca";
		eecec_b = "/pinctrl@ff634480/ee_cecb";
		internal_eth_pins = "/pinctrl@ff634480/internal_eth_pins";
		internal_gpio_pins = "/pinctrl@ff634480/internal_gpio_pins";
		external_eth_pins = "/pinctrl@ff634480/external_eth_pins";
		jtag_apee_pins = "/pinctrl@ff634480/jtag_apee_pin";
		tdmout_a = "/pinctrl@ff634480/tdmout_a";
		tdmin_a = "/pinctrl@ff634480/tdmin_a";
		tdmb_mclk = "/pinctrl@ff634480/tdmb_mclk";
		tdmout_b = "/pinctrl@ff634480/tdmout_b";
		tdmin_b = "/pinctrl@ff634480/tdmin_b";
		tdmc_mclk = "/pinctrl@ff634480/tdmc_mclk";
		tdmout_c = "/pinctrl@ff634480/tdmout_c";
		tdmin_c = "/pinctrl@ff634480/tdmin_c";
		spdifin = "/pinctrl@ff634480/spdifin";
		pdmin = "/pinctrl@ff634480/pdmin";
		bl_pwm_off_pins = "/pinctrl@ff634480/bl_pwm_off_pin";
		clk12_24_z_pins = "/pinctrl@ff634480/clk12_24_z_pins";
		gen_clk_ee_z = "/pinctrl@ff634480/gen_clk_ee_z";
		cam_dvp_pins = "/pinctrl@ff634480/cam_dvp_pins";
		spdifout = "/pinctrl@ff634480/spdifout";
		audio_data = "/audio_data";
		dwc3 = "/dwc3@ff500000";
		usb2_phy_v2 = "/usb2phy@ffe09000";
		usb3_phy_v2 = "/usb3phy@ffe09080";
		dwc2_a = "/dwc2_a@ff400000";
		wdt = "/watchdog@0xffd0f0d0";
		saradc = "/saradc";
		power_ctrl = "/power_ctrl@ff8000e8";
		cbus = "/soc/cbus@ffd00000";
		gpio_intc = "/soc/cbus@ffd00000/interrupt-controller@f080";
		pwm_ab = "/soc/cbus@ffd00000/pwm@1b000";
		pwm_cd = "/soc/cbus@ffd00000/pwm@1a000";
		pwm_ef = "/soc/cbus@ffd00000/pwm@19000";
		i2c0 = "/soc/cbus@ffd00000/i2c@1f000";
		i2c1 = "/soc/cbus@ffd00000/i2c@1e000";
		hym8563 = "/soc/cbus@ffd00000/i2c@1e000/hym8563@51";
		i2c2 = "/soc/cbus@ffd00000/i2c@1d000";
		i2c3 = "/soc/cbus@ffd00000/i2c@1c000";
		ad82584f_62 = "/soc/cbus@ffd00000/i2c@1c000/ad82584f_62@62";
		spicc0 = "/soc/cbus@ffd00000/spi@13000";
		spicc1 = "/soc/cbus@ffd00000/spi@15000";
		aobus = "/soc/aobus@ff800000";
		aoclkc = "/soc/aobus@ff800000/clock-controller@0";
		pwm_AO_ab = "/soc/aobus@ff800000/pwm@7000";
		pwm_AO_cd = "/soc/aobus@ff800000/pwm@2000";
		i2c_AO = "/soc/aobus@ff800000/i2c@5000";
		i2c_AO_slave = "/soc/aobus@ff800000/i2c_slave@6000";
		uart_AO = "/soc/aobus@ff800000/serial@3000";
		uart_AO_B = "/soc/aobus@ff800000/serial@4000";
		periphs = "/soc/periphs@ff634400";
		hiubus = "/soc/hiubus@ff63c000";
		clkc = "/soc/hiubus@ff63c000/clock-controller@0";
		clkc_b = "/soc/hiubus@ff63c000/clock-controller@1";
		audiobus = "/soc/audiobus@0xFF660000";
		clkaudio = "/soc/audiobus@0xFF660000/audio_clocks";
		tdma = "/soc/audiobus@0xFF660000/tdm@0";
		tdmb = "/soc/audiobus@0xFF660000/tdm@1";
		tdmc = "/soc/audiobus@0xFF660000/tdm@2";
		tdmlb = "/soc/audiobus@0xFF660000/tdm@3";
		spdifa = "/soc/audiobus@0xFF660000/spdif@0";
		spdifb = "/soc/audiobus@0xFF660000/spdif@1";
		pdm = "/soc/audiobus@0xFF660000/pdm";
		earc = "/soc/audiobus@0xFF660000/earc";
		asrca = "/soc/audiobus@0xFF660000/resample@0";
		vad = "/soc/audiobus@0xFF660000/vad";
		loopbacka = "/soc/audiobus@0xFF660000/loopback@0";
		loopbackb = "/soc/audiobus@0xFF660000/loopback@1";
		aed = "/soc/audiobus@0xFF660000/effect";
		remote = "/rc@0xff808040";
		custom_maps = "/custom_maps";
		map_0 = "/custom_maps/map_0";
		map_1 = "/custom_maps/map_1";
		map_2 = "/custom_maps/map_2";
		uart_A = "/serial@ffd24000";
		uart_B = "/serial@ffd23000";
		uart_C = "/serial@ffd22000";
		pcie_A = "/pcieA@fc000000";
		amhdmitx = "/amhdmitx";
		vend_data = "/amhdmitx/vend_data";
		aocec = "/aocec";
		vdin0 = "/vdin0";
		vdin1 = "/vdin1";
		canvas = "/canvas";
		codec_io = "/codec_io";
		meson_fb = "/fb";
		irblaster = "/meson-irblaster";
		sd_emmc_c = "/emmc@ffe07000";
		sd_emmc_b = "/sd@ffe05000";
		sd_emmc_a = "/sdio@ffe03000";
		nand = "/nfc@0";
		bootloader = "/nfc@0/bootloader";
		nandnormal = "/nfc@0/nandnormal";
		nand_partitions = "/nfc@0/nand_partition";
		vddcpu0 = "/pwmao_d-regulator";
		defendkey = "/defendkey";
		efuse = "/efuse";
		partitions = "/partitions";
		logo = "/partitions/logo";
		recovery = "/partitions/recovery";
		misc = "/partitions/misc";
		dtbo = "/partitions/dtbo";
		cri_data = "/partitions/cri_data";
		rsv = "/partitions/rsv";
		metadata = "/partitions/metadata";
		vbmeta = "/partitions/vbmeta";
		param = "/partitions/param";
		boot = "/partitions/boot";
		tee = "/partitions/tee";
		vendor = "/partitions/vendor";
		odm = "/partitions/odm";
		system = "/partitions/system";
		product = "/partitions/product";
		cache = "/partitions/cache";
		data = "/partitions/data";
		lcd = "/lcd";
		bl_pwm_conf = "/bl_pwm_conf";
		secmon_reserved = "/reserved-memory/linux,secmon";
		secos_reserved = "/reserved-memory/linux,secos";
		logo_reserved = "/reserved-memory/linux,meson-fb";
		ion_cma_reserved = "/reserved-memory/linux,ion-dev";
		di_cma_reserved = "/reserved-memory/linux,di_cma";
		ppmgr_reserved = "/reserved-memory/linux,ppmgr";
		codec_mm_cma = "/reserved-memory/linux,codec_mm_cma";
		codec_mm_reserved = "/reserved-memory/linux,codec_mm_reserved";
		vdin0_cma_reserved = "/reserved-memory/linux,vdin0_cma";
		vdin1_cma_reserved = "/reserved-memory/linux,vdin1_cma";
		vm0_cma_reserved = "/reserved-memory/linux,vm0_cma";
		amlogic_battery = "/dummy-battery";
		amlogic_charger = "/dummy-charger";
		wifi_pwm_conf = "/wifi_pwm_conf";
		picdec_cma_reserved = "/linux,picdec";
		keysn_0 = "/unifykey/key_0";
		keysn_1 = "/unifykey/key_1";
		keysn_2 = "/unifykey/key_2";
		keysn_3 = "/unifykey/key_3";
		keysn_4 = "/unifykey/key_4";
		keysn_5 = "/unifykey/key_5";
		keysn_6 = "/unifykey/key_6";
		keysn_7 = "/unifykey/key_7";
		keysn_8 = "/unifykey/key_8";
		keysn_9 = "/unifykey/key_9";
		keysn_10 = "/unifykey/key_10";
		keysn_11 = "/unifykey/key_11";
		keysn_12 = "/unifykey/key_12";
		keysn_13 = "/unifykey/key_13";
		keysn_14 = "/unifykey/key_14";
		keysn_15 = "/unifykey/key_15";
		efusekey = "/efusekey";
		key_0 = "/efusekey/key_0";
		key_1 = "/efusekey/key_1";
		key_2 = "/efusekey/key_2";
		key_3 = "/efusekey/key_3";
		dummy_codec = "/dummy";
		pdm_codec = "/dummy";
		amlogic_codec = "/t9015";
		audio_effect = "/eqdrc";
		tdmacpu = "/auge_sound/aml-audio-card,dai-link@0/cpu";
		tdmacodec = "/auge_sound/aml-audio-card,dai-link@0/codec";
		tdmbcodec = "/auge_sound/aml-audio-card,dai-link@1/codec";
		tdmccodec = "/auge_sound/aml-audio-card,dai-link@2/codec";
		audiolocker = "/locker";
		p_tsensor = "/p_tsensor@ff634594";
		d_tsensor = "/d_tsensor@ff800228";
		meson_cooldev = "/meson-cooldev@0";
		cpufreq_cool0 = "/meson-cooldev@0/cpufreq_cool0";
		cpucore_cool0 = "/meson-cooldev@0/cpucore_cool0";
		gpufreq_cool0 = "/meson-cooldev@0/gpufreq_cool0";
		gpucore_cool0 = "/meson-cooldev@0/gpucore_cool0";
		soc_thermal = "/thermal-zones/soc_thermal";
		pswitch_on = "/thermal-zones/soc_thermal/trips/trip-point@0";
		pcontrol = "/thermal-zones/soc_thermal/trips/trip-point@1";
		phot = "/thermal-zones/soc_thermal/trips/trip-point@2";
		pcritical = "/thermal-zones/soc_thermal/trips/trip-point@3";
		ddr_thermal = "/thermal-zones/ddr_thermal";
		dswitch_on = "/thermal-zones/ddr_thermal/trips/trip-point@0";
		dcontrol = "/thermal-zones/ddr_thermal/trips/trip-point@1";
		dhot = "/thermal-zones/ddr_thermal/trips/trip-point@2";
		dcritical = "/thermal-zones/ddr_thermal/trips/trip-point@3";
		cpu_opp_table0 = "/cpu_opp_table0";
	};
};
